VERSION ""

NS_ :

BS_:

BU_: XXX CLOCK HUD H_U DATC CCP KMA_TMU CUBIS TMU IPM RSE_R RRC CGW RSE_L AMP EDT SWRC IBOX CLU FHCU ASD MON AVM KBD IAP ODS _4WD BCM MDPS AAF_Tester AEMC SMK EPB MTS EVP TPMS LPI DI_BOX SPAS EMS LCA TCU FATC AFLS FPCM SCC AHLS ABS SNV OPI PGS SAS AAF Dummy LDWS_LKAS LVR ESC PSB ECS ACU REA

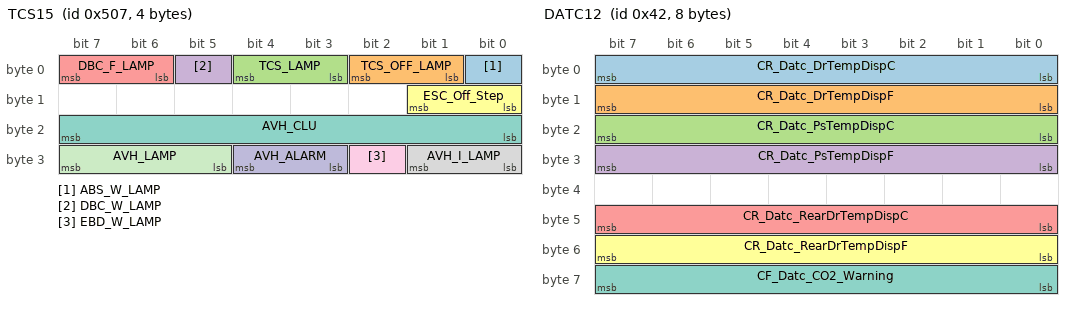
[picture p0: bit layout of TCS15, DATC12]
BO_ 1287 TCS15: 4 ESC
 SG_ ABS_W_LAMP : 0|1@1+ (1.0,0.0) [0.0|1.0] ""  _4WD,CLU,CUBIS,IBOX
 SG_ TCS_OFF_LAMP : 1|2@1+ (1.0,0.0) [0.0|1.0] ""  _4WD,ACU,CLU
 SG_ TCS_LAMP : 3|2@1+ (1.0,0.0) [0.0|3.0] ""  _4WD,ACU,CLU,CUBIS,IBOX,SCC
 SG_ DBC_W_LAMP : 5|1@1+ (1.0,0.0) [0.0|1.0] ""  _4WD,CLU
 SG_ DBC_F_LAMP : 6|2@1+ (1.0,0.0) [0.0|3.0] ""  _4WD,CLU
 SG_ ESC_Off_Step : 8|2@1+ (1.0,0.0) [0.0|3.0] ""  CLU
 SG_ AVH_CLU : 16|8@1+ (1.0,0.0) [0.0|255.0] ""  CLU,EPB
 SG_ AVH_I_LAMP : 24|2@1+ (1.0,0.0) [0.0|3.0] ""  EPB
 SG_ EBD_W_LAMP : 26|1@1+ (1.0,0.0) [0.0|1.0] ""  _4WD,CLU
 SG_ AVH_ALARM : 27|2@1+ (1.0,0.0) [0.0|3.0] ""  CLU
 SG_ AVH_LAMP : 29|3@1+ (1.0,0.0) [0.0|7.0] ""  CLU,EPB,SPAS

BO_ 916 TCS13: 8 ESC
 SG_ aBasis : 0|11@1+ (0.01,-10.23) [-10.23|10.24] "m/s^2"  EMS,SCC
 SG_ BrakeLight : 11|1@1+ (1.0,0.0) [0.0|1.0] ""  CLU,EMS,SCC
 SG_ DCEnable : 12|1@1+ (1.0,0.0) [0.0|1.0] ""  EMS,SCC
 SG_ AliveCounterTCS : 13|3@1+ (1.0,0.0) [0.0|7.0] ""  EMS,SCC
 SG_ Pre_TCS_CTL : 16|1@1+ (1.0,0.0) [0.0|1.0] ""  Vector__XXX
 SG_ EBA_ACK : 17|1@1+ (1.0,0.0) [0.0|1.0] ""  Vector__XXX
 SG_ FCA_ACK : 18|1@1+ (1.0,0.0) [0.0|1.0] ""  Vector__XXX
 SG_ DF_BF_STAT : 19|2@1+ (1.0,0.0) [0.0|3.0] ""  BCW
 SG_ SCCReqLim : 21|2@1+ (1.0,0.0) [0.0|3.0] ""  SCC
 SG_ TQI_SCC : 23|9@1+ (0.390625,0.0) [0.0|199.609375] "%"  Vector__XXX
 SG_ ACCEL_REF_ACC : 32|11@1+ (0.01,-10.23) [-10.23|10.24] "m/s^2"  EMS,SCC
 SG_ ACCEnable : 43|2@1+ (1.0,0.0) [0.0|3.0] ""  EMS,SCC
 SG_ DriverOverride : 45|2@1+ (1.0,0.0) [0.0|3.0] ""  EMS,SCC
 SG_ StandStill : 47|1@1+ (1.0,0.0) [0.0|1.0] ""  EMS,SCC
 SG_ CheckSum_TCS3 : 48|4@1+ (1.0,0.0) [0.0|15.0] ""  EMS,SCC
 SG_ ACC_EQUIP : 52|1@1+ (1.0,0.0) [0.0|1.0] ""  EMS,SCC
 SG_ PBRAKE_ACT : 53|1@1+ (1.0,0.0) [0.0|1.0] ""  EMS,SCC
 SG_ ACC_REQ : 54|1@1+ (1.0,0.0) [0.0|1.0] ""  EMS
 SG_ DriverBraking : 55|1@1+ (1.0,0.0) [0.0|1.0] ""  EMS,SCC
 SG_ CF_VSM_Coded : 56|1@1+ (1.0,0.0) [0.0|1.0] ""  SCC
 SG_ CF_VSM_Avail : 57|2@1+ (1.0,0.0) [0.0|3.0] ""  CLU,SCC
 SG_ CF_VSM_Handshake : 59|1@1+ (1.0,0.0) [0.0|1.0] ""  SCC
 SG_ CF_DriBkeStat : 60|1@1+ (1.0,0.0) [0.0|1.0] ""  SCC
 SG_ CF_VSM_ConfSwi : 61|2@1+ (1.0,0.0) [0.0|3.0] ""  SCC
 SG_ AEB_EQUIP : 63|1@1+ (1.0,0.0) [0.0|1.0] ""  SCC

BO_ 1345 CGW1: 8 BCM
 SG_ CF_Gway_IGNSw : 0|3@1+ (1.0,0.0) [0.0|7.0] ""  AVM,CLU,ECS,EMS,EPB,ESC,IBOX,LVR,MDPS,SAS,SCC,ECS,EMS,EPB,ESC,IBOX,LVR,MDPS,SAS,SCC
 SG_ CF_Gway_RKECmd : 3|3@1+ (1.0,0.0) [0.0|7.0] ""  CLU,ECS,EMS,IBOX,ECS,EMS,IBOX
 SG_ CF_Gway_DrvKeyLockSw : 6|1@1+ (1.0,0.0) [0.0|1.0] ""  ECS,EMS,IBOX,ECS,EMS,IBOX
 SG_ CF_Gway_DrvKeyUnlockSw : 7|1@1+ (1.0,0.0) [0.0|1.0] ""  ECS,EMS,IBOX,ECS,EMS,IBOX
 SG_ CF_Gway_DrvDrSw : 8|2@1+ (1.0,0.0) [0.0|3.0] ""  CLU,ECS,EMS,EPB,ESC,IBOX,SCC,TCU,ECS,EMS,EPB,ESC,IBOX,SCC,TCU
 SG_ CF_Gway_DrvSeatBeltSw : 10|2@1+ (1.0,0.0) [0.0|3.0] ""  EMS,EPB,ESC,IBOX,PSB,TCU,EMS,EPB,ESC,IBOX,PSB,TCU
 SG_ CF_Gway_TrunkTgSw : 12|2@1+ (1.0,0.0) [0.0|3.0] ""  CLU,ECS,EMS,EPB,ESC,IBOX,ECS,EMS,EPB,ESC,IBOX
 SG_ CF_Gway_AstSeatBeltSw : 14|2@1+ (1.0,0.0) [0.0|3.0] ""  IBOX,PSB,IBOX,PSB
 SG_ CF_Gway_SMKOption : 16|1@1+ (1.0,0.0) [0.0|1.0] ""  CLU,EMS,IBOX,EMS,IBOX,SMK
 SG_ CF_Gway_HoodSw : 17|2@1+ (1.0,0.0) [0.0|3.0] ""  CLU,EMS,EPB,ESC,IBOX,EMS,EPB,ESC,IBOX
 SG_ CF_Gway_TurnSigLh : 19|2@1+ (1.0,0.0) [0.0|3.0] ""  CLU,EMS,IBOX,LCA,LDWS_LKAS,SCC,EMS,IBOX,LCA,LDWS_LKAS,SCC
 SG_ CF_Gway_WiperIntT : 21|3@1+ (1.0,0.0) [0.0|7.0] ""  CLU,EMS,IBOX,LDWS_LKAS,EMS,ESC,IBOX,LDWS_LKAS
 SG_ CF_Gway_WiperIntSw : 24|1@1+ (1.0,0.0) [0.0|1.0] ""  CLU,EMS,IBOX,LDWS_LKAS,EMS,ESC,IBOX,LDWS_LKAS
 SG_ CF_Gway_WiperLowSw : 25|1@1+ (1.0,0.0) [0.0|1.0] ""  CLU,EMS,IBOX,LDWS_LKAS,EMS,ESC,IBOX,LDWS_LKAS
 SG_ CF_Gway_WiperHighSw : 26|1@1+ (1.0,0.0) [0.0|1.0] ""  CLU,EMS,IBOX,LDWS_LKAS,EMS,ESC,IBOX,LDWS_LKAS
 SG_ CF_Gway_WiperAutoSw : 27|1@1+ (1.0,0.0) [0.0|1.0] ""  CLU,EMS,IBOX,LDWS_LKAS,EMS,ESC,IBOX,LDWS_LKAS
 SG_ CF_Gway_RainSnsState : 28|3@1+ (1.0,0.0) [0.0|7.0] ""  AFLS,EMS,IBOX,LDWS_LKAS,AFLS,EMS,ESC,IBOX,LDWS_LKAS
 SG_ CF_Gway_HeadLampLow : 31|1@1+ (1.0,0.0) [0.0|1.0] ""  AFLS,CLU,EMS,IBOX,LDWS_LKAS,SNV,AFLS,EMS,IBOX,LDWS_LKAS,SNV
 SG_ CF_Gway_HeadLampHigh : 32|1@1+ (1.0,0.0) [0.0|1.0] ""  AFLS,CLU,EMS,IBOX,LDWS_LKAS,AFLS,EMS,IBOX,LDWS_LKAS
 SG_ CF_Gway_HazardSw : 33|2@1+ (1.0,0.0) [0.0|3.0] ""  ABS,EMS,ESC,IBOX,LCA,LDWS_LKAS,ABS,EMS,ESC,IBOX,LCA,LDWS_LKAS
 SG_ CF_Gway_AstDrSw : 35|1@1+ (1.0,0.0) [0.0|1.0] ""  CLU,IBOX,IBOX
 SG_ CF_Gway_DefoggerRly : 36|1@1+ (1.0,0.0) [0.0|1.0] ""  EMS,IBOX,EMS,IBOX
 SG_ CF_Gway_ALightStat : 37|1@1+ (1.0,0.0) [0.0|1.0] ""  AFLS,IBOX,LDWS_LKAS,AFLS,IBOX,LDWS_LKAS
 SG_ CF_Gway_LightSwState : 38|2@1+ (1.0,0.0) [0.0|3.0] ""  AFLS,IBOX,LDWS_LKAS,AFLS,IBOX,LDWS_LKAS
 SG_ CF_Gway_Frt_Fog_Act : 40|1@1+ (1.0,0.0) [0.0|1.0] ""  AFLS,CLU,IBOX,LDWS_LKAS,AFLS,IBOX,LDWS_LKAS
 SG_ CF_Gway_TSigRHSw : 41|1@1+ (1.0,0.0) [0.0|1.0] ""  IBOX,LDWS_LKAS,IBOX,LDWS_LKAS
 SG_ CF_Gway_TSigLHSw : 42|1@1+ (1.0,0.0) [0.0|1.0] ""  IBOX,LDWS_LKAS,IBOX,LDWS_LKAS
 SG_ CF_Gway_DriveTypeOption : 43|1@1+ (1.0,0.0) [0.0|1.0] ""  CLU,IBOX,LDWS_LKAS,IBOX,LDWS_LKAS
 SG_ CF_Gway_StarterRlyState : 44|1@1+ (1.0,0.0) [0.0|1.0] ""  EMS,IBOX,EMS,IBOX,SMK
 SG_ CF_Gway_PassiveAccessLock : 45|2@1+ (1.0,0.0) [0.0|7.0] ""  CLU,ECS,EMS,IBOX,ECS,EMS,IBOX,SMK
 SG_ CF_Gway_WiperMistSw : 47|1@1+ (1.0,0.0) [0.0|1.0] ""  CLU,EMS,IBOX,LDWS_LKAS
 SG_ CF_Gway_PassiveAccessUnlock : 48|2@1+ (1.0,0.0) [0.0|7.0] ""  CLU,ECS,EMS,IBOX,ECS,EMS,IBOX,SMK
 SG_ CF_Gway_RrSunRoofOpenState : 50|1@1+ (1.0,0.0) [0.0|1.0] ""  CLU,DATC,IBOX
 SG_ CF_Gway_PassingSW : 51|1@1+ (1.0,0.0) [0.0|1.0] ""  AFLS,IBOX,LDWS_LKAS,AFLS,IBOX,LDWS_LKAS
 SG_ CF_Gway_HBAControlMode : 52|1@1+ (1.0,0.0) [0.0|1.0] ""  IBOX,LDWS_LKAS,IBOX,LDWS_LKAS
 SG_ CF_Gway_HLpHighSw : 53|1@1+ (1.0,0.0) [0.0|1.0] ""  IBOX,LDWS_LKAS,IBOX,LDWS_LKAS
 SG_ CF_Gway_InhibitRMT : 54|2@1+ (1.0,0.0) [0.0|3.0] ""  EMS,EPB,ESC,IBOX,LCA,LDWS_LKAS,MDPS,PGS,SCC,SPAS,TPMS,EPB,ESC,IBOX,LCA,LDWS_LKAS,PGS,SCC,SPAS,TPMS
 SG_ CF_Gway_RainSnsOption : 56|1@1+ (1.0,0.0) [0.0|1.0] ""  CLU
 SG_ C_SunRoofOpenState : 57|1@1+ (1.0,0.0) [0.0|1.0] ""  CLU,DATC,IBOX,DATC,IBOX
 SG_ CF_Gway_Ign1 : 58|1@1+ (1.0,0.0) [0.0|1.0] ""  CLU
 SG_ CF_Gway_Ign2 : 59|1@1+ (1.0,0.0) [0.0|1.0] ""  CLU
 SG_ CF_Gway_ParkBrakeSw : 60|2@1+ (1.0,0.0) [0.0|3.0] ""  CLU,ESC,IBOX,SCC,ESC,IBOX,SCC
 SG_ CF_Gway_TurnSigRh : 62|2@1+ (1.0,0.0) [0.0|3.0] ""  CLU,EMS,IBOX,LCA,LDWS_LKAS,SCC,EMS,IBOX,LCA,LDWS_LKAS,SCC

BO_ 1342 LKAS12: 6 LDWS_LKAS
 SG_ CF_Lkas_TsrSlifOpt : 10|2@1+ (1.0,0.0) [0.0|3.0] ""  CLU
 SG_ CF_LkasTsrStatus : 12|2@1+ (1.0,0.0) [0.0|3.0] ""  CLU
 SG_ CF_Lkas_TsrSpeed_Display_Clu : 16|8@1+ (1.0,0.0) [0.0|255.0] ""  CLU
 SG_ CF_LkasTsrSpeed_Display_Navi : 24|8@1+ (1.0,0.0) [0.0|255.0] ""  BCM,CLU
 SG_ CF_Lkas_TsrAddinfo_Display : 32|2@1+ (1.0,0.0) [0.0|3.0] ""  CLU
 SG_ CF_LkasDawStatus : 40|3@1+ (1,0) [0|7] "" CLU
 SG_ CF_Lkas_Daw_USM : 39|3@1+ (1,0) [0|7] "" CLU

BO_ 832 LKAS11: 8 LDWS_LKAS
    SG_ CF_Lkas_LdwsActivemode : 0|2@1+ (1,0) [0|3] "" CLU,IBOX,PSB
    SG_ CF_Lkas_LdwsSysState : 2|4@1+ (1.0,0.0) [0.0|15.0] ""  CLU,IBOX,PSB
    SG_ CF_Lkas_SysWarning : 6|4@1+ (1.0,0.0) [0.0|15.0] ""  BCM,CLU
    SG_ CF_Lkas_LdwsLHWarning : 10|2@1+ (1.0,0.0) [0.0|3.0] ""  BCM,CLU,PSB
    SG_ CF_Lkas_LdwsRHWarning : 12|2@1+ (1.0,0.0) [0.0|3.0] ""  BCM,CLU,PSB
    SG_ CF_Lkas_HbaLamp : 14|1@1+ (1.0,0.0) [0.0|1.0] ""  CLU
    SG_ CF_Lkas_FcwBasReq : 15|1@1+ (1.0,0.0) [0.0|1.0] ""  ABS,ESC
    SG_ CR_Lkas_StrToqReq : 16|11@1+ (1.0,-1024.0) [-1024.0|1024.0] ""  MDPS
    SG_ CF_Lkas_ActToi : 27|1@1+ (1.0,0.0) [0.0|1.0] ""  MDPS
    SG_ CF_Lkas_ToiFlt : 28|1@1+ (1.0,0.0) [0.0|1.0] ""  MDPS
    SG_ CF_Lkas_HbaSysState : 29|3@1+ (1.0,0.0) [0.0|7.0] ""  BCM,CLU
    SG_ CF_Lkas_FcwOpt : 32|2@1+ (1.0,0.0) [0.0|3.0] ""  CLU
    SG_ CF_Lkas_HbaOpt : 34|2@1+ (1.0,0.0) [0.0|1.0] ""  BCM,CGW
    SG_ CF_Lkas_MsgCount : 36|4@1+ (1.0,0.0) [0.0|15.0] ""  CLU,MDPS
    SG_ CF_Lkas_FcwSysState : 40|3@1+ (1.0,0.0) [0.0|7.0] ""  CLU
    SG_ CF_Lkas_FcwCollisionWarning : 43|2@1+ (1.0,0.0) [0.0|3.0] ""  CLU
    SG_ CF_Lkas_FusionState : 45|2@1+ (1.0,0.0) [0.0|3.0] ""  SCC
    SG_ CF_Lkas_Unknown1 : 47|1@1+ (1.0,0.0) [0.0|1.0] "" XXX
    SG_ CF_Lkas_Chksum : 48|8@1+ (1.0,0.0) [0.0|255.0] ""  MDPS
    SG_ CF_Lkas_FcwOpt_USM : 56|3@1+ (1.0,0.0) [0.0|7.0] ""  CLU
    SG_ CF_Lkas_LdwsOpt_USM : 59|3@1+ (1.0,0.0) [0.0|7.0] ""  CLU,MDPS
    SG_ CF_Lkas_Unknown2 : 62|2@1+ (1.0,0.0) [0.0|1.0] "" XXX

BO_ 52 HU_DATC_E_02: 8 H_U
    SG_ HU_DATC_DrTempUpDn : 1|2@0+ (1,0) [0|0] ""  CGW,CLU,DATC,IPM
    SG_ HU_DATC_PsTempUpDn : 3|2@0+ (1,0) [0|0] ""  CGW,CLU,DATC,IPM
    SG_ HU_DATC_RlTempUpDn : 5|2@0+ (1,0) [0|0] ""  CGW,CLU,DATC,IPM
    SG_ HU_DATC_RrTempUpDn : 7|2@0+ (1,0) [0|0] ""  CGW,CLU,DATC,IPM
    SG_ HU_DATC_MainBlower : 11|4@0+ (1,0) [0|0] ""  CGW,CLU,DATC,IPM
    SG_ HU_DATC_SubBlower : 15|4@0+ (1,0) [0|0] ""  CGW,CLU,DATC,IPM
    SG_ HU_DATC_RearBlower : 19|4@0+ (1,0) [0|0] ""  CGW,CLU,DATC,IPM
    SG_ HU_DATCRearPsModeSet : 23|4@0+ (1,0) [0|0] ""  CGW,CLU
    SG_ HU_DATC_FrontModeSet : 27|4@0+ (1,0) [0|0] ""  CGW,CLU,DATC,IPM
    SG_ HU_DATC_RearModeSet : 31|4@0+ (1,0) [0|0] ""  CGW,CLU,DATC,IPM
    SG_ HU_DATC_AutoSet : 33|2@0+ (1,0) [0|0] ""  CGW,CLU,DATC,IPM
    SG_ HU_DATC_OffReq : 35|2@0+ (1,0) [0|0] ""  CGW,CLU,DATC,IPM
    SG_ HU_DATC_IntakeSet : 37|2@0+ (1,0) [0|0] ""  CGW,CLU,DATC,IPM
    SG_ HU_DATC_RearOnOffSet : 39|2@0+ (1,0) [0|0] ""  CGW,CLU,DATC,IPM
    SG_ HU_DATC_AcSet : 41|2@0+ (1,0) [0|0] ""  CGW,CLU,DATC,IPM
    SG_ HU_DATC_AqsSet : 43|2@0+ (1,0) [0|0] ""  CGW,CLU,DATC,IPM
    SG_ HU_DATC_FrontDefog : 45|2@0+ (1,0) [0|0] ""  CGW,CLU,DATC,IPM
    SG_ HU_DATC_RearDefog : 47|2@0+ (1,0) [0|0] ""  CGW,CLU,DATC,IPM
    SG_ HU_DATC_ZoneControl : 49|2@0+ (1,0) [0|0] ""  CGW,CLU,DATC,IPM
    SG_ HU_DATC_CO2Set : 51|2@0+ (1,0) [0|0] ""  CGW,CLU,DATC,IPM
    SG_ DATC_SmartVentOnOffSet : 53|2@0+ (1,0) [0|0] ""  CGW,CLU,DATC,IPM
    SG_ DATC_ADSOnOffSet : 55|2@0+ (1,0) [0|0] ""  CGW,CLU
    SG_ HU_DATC_RearAutoDisp : 57|2@0+ (1,0) [0|0] ""  CGW,CLU
    SG_ HU_DATC_RearOffDisp : 59|2@0+ (1,0) [0|0] ""  CGW,CLU

BO_ 66 DATC12: 8 DATC
    SG_ CR_Datc_DrTempDispC : 0|8@1+ (0.5,14.0) [15.0|32.0] "deg"  CLU,IBOX
    SG_ CR_Datc_DrTempDispF : 8|8@1+ (1.0,56.0) [58.0|90.0] "deg"  CLU,IBOX
    SG_ CR_Datc_PsTempDispC : 16|8@1+ (0.5,14.0) [15.0|32.0] "deg"  CLU,IBOX
    SG_ CR_Datc_PsTempDispF : 24|8@1+ (1.0,56.0) [58.0|90.0] "deg"  CLU,IBOX
    SG_ CR_Datc_RearDrTempDispC : 40|8@1+ (0.5,14.0) [15.0|32.0] "deg"  CLU
    SG_ CR_Datc_RearDrTempDispF : 48|8@1+ (1.0,58.0) [58.0|90.0] "deg"  CLU
    SG_ CF_Datc_CO2_Warning : 56|8@1+ (1.0,0.0) [0.0|3.0] ""  CLU

BO_ 67 DATC13: 8 DATC
    SG_ CF_Datc_TempDispUnit : 0|2@1+ (1.0,0.0) [0.0|3.0] ""  CLU,IBOX
    SG_ CF_Datc_ModDisp : 2|4@1+ (1.0,0.0) [0.0|15.0] ""  CLU
    SG_ CF_Datc_IonClean : 6|2@1+ (1.0,0.0) [0.0|3.0] ""  CLU
    SG_ CF_Datc_ChgReqDisp : 8|2@1+ (1.0,0.0) [0.0|3.0] ""  CLU
    SG_ CF_Datc_IntakeDisp : 10|2@1+ (1.0,0.0) [0.0|3.0] ""  CLU
    SG_ CF_Datc_AutoDisp : 12|2@1+ (1.0,0.0) [0.0|3.0] ""  CLU
    SG_ CF_Datc_FrDefLed : 14|2@1+ (1.0,0.0) [0.0|3.0] ""  CLU,IBOX
    SG_ CF_Datc_AutoDefogBlink : 16|2@1+ (1.0,0.0) [0.0|3.0] ""  CLU
    SG_ CF_Datc_ClmScanDisp : 18|2@1+ (1.0,0.0) [0.0|3.0] ""  CLU
    SG_ CF_Datc_AqsDisp : 20|2@1+ (1.0,0.0) [0.0|3.0] ""  CLU
    SG_ CF_Datc_AcDisp : 22|2@1+ (1.0,0.0) [0.0|3.0] ""  CLU
    SG_ CF_Datc_OpSts : 25|3@1+ (1.0,0.0) [0.0|7.0] ""  CLU
    SG_ CF_Mtc_MaxAcDisp : 28|2@1+ (1.0,0.0) [0.0|3.0] ""  CLU
    SG_ CF_Datc_DualDisp : 30|2@1+ (1.0,0.0) [0.0|3.0] ""  CLU
    SG_ CF_Datc_PwrInf : 32|4@1+ (1.0,0.0) [0.0|15.0] ""  CLU
    SG_ CF_Datc_RearManual : 38|2@1+ (1.0,0.0) [0.0|3.0] ""  CLU
    SG_ CF_Datc_RearAutoDisp : 40|2@1+ (1.0,0.0) [0.0|1.0] ""  CLU
    SG_ CF_Datc_RearOffDisp : 42|2@1+ (1.0,0.0) [0.0|3.0] ""  CLU
    SG_ CF_Datc_RearClimateScnDisp : 44|2@1+ (1.0,0.0) [0.0|3.0] ""  CLU
    SG_ CF_Datc_RearChgReqDisp : 46|2@1+ (1.0,0.0) [0.0|3.0] ""  CLU
    SG_ CF_Datc_RearModDisp : 48|4@1+ (1.0,0.0) [0.0|15.0] ""  CLU
    SG_ CF_Datc_RearBlwDisp : 52|4@1+ (1.0,0.0) [0.0|15.0] ""  CLU
    SG_ CF_Datc_PSModDisp : 56|4@1+ (1.0,0.0) [0.0|15.0] ""  CLU
    SG_ CF_Datc_FrontBlwDisp : 60|4@1+ (1.0,0.0) [0.0|15.0] ""  CLU,IBOX

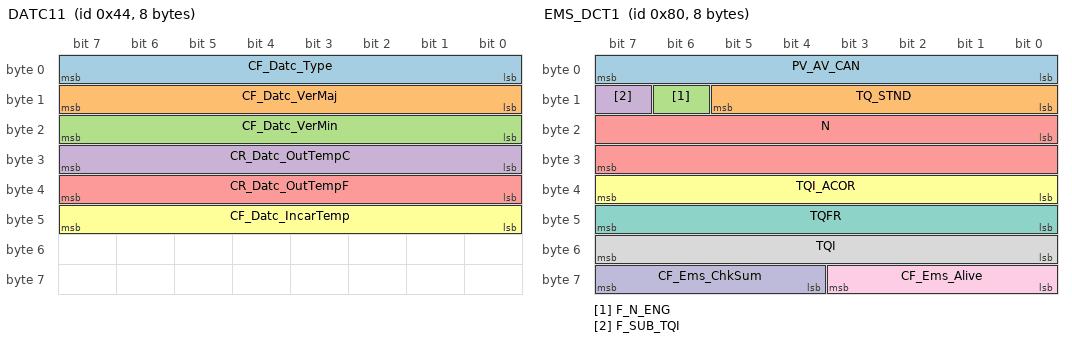
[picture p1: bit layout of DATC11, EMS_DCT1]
BO_ 68 DATC11: 8 DATC
    SG_ CF_Datc_Type : 0|8@1+ (1.0,0.0) [0.0|255.0] ""  CLU
    SG_ CF_Datc_VerMaj : 8|8@1+ (1.0,0.0) [0.0|255.0] ""  CLU
    SG_ CF_Datc_VerMin : 16|8@1+ (1.0,0.0) [0.0|255.0] ""  CLU
    SG_ CR_Datc_OutTempC : 24|8@1+ (0.5,-41.0) [-41.0|86.5] "deg"  CLU,FPCM
    SG_ CR_Datc_OutTempF : 32|8@1+ (1.0,-42.0) [-42.0|213.0] "deg"  CLU
    SG_ CF_Datc_IncarTemp : 40|8@1+ (0.5,-40.0) [-40.0|60.0] "deg"  BCM,CLU

BO_ 128 EMS_DCT1: 8 XXX
    SG_ PV_AV_CAN : 0|8@1+ (0.3906,0) [0|99.603] "%" XXX
    SG_ TQ_STND : 8|6@1+ (10,0) [0|630] "Nm" XXX
    SG_ F_N_ENG : 14|1@1+ (1,0) [0|1] "" XXX
    SG_ F_SUB_TQI : 15|1@1+ (1,0) [0|1] "" XXX
    SG_ N : 16|16@1+ (0.25,0) [0|16383.8] "rpm" XXX
    SG_ TQI_ACOR : 32|8@1+ (0.390625,0) [0|99.6094] "%" XXX
    SG_ TQFR : 40|8@1+ (0.390625,0) [0|99.6094] "%" XXX
    SG_ TQI : 48|8@1+ (0.390625,0) [0|99.6094] "%" XXX
    SG_ CF_Ems_Alive : 56|4@1+ (1,0) [0|15] "" XXX
    SG_ CF_Ems_ChkSum : 60|4@1+ (1,0) [0|15] "" XXX

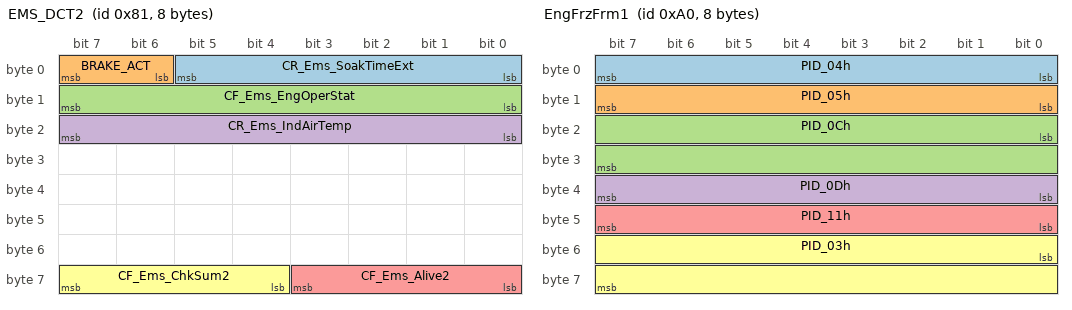
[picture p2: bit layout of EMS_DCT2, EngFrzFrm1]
BO_ 129 EMS_DCT2: 8 XXX
    SG_ CR_Ems_SoakTimeExt : 0|6@1+ (5,0) [0|315] "Min" XXX
    SG_ BRAKE_ACT : 6|2@1+ (1,0) [0|3] "" XXX
    SG_ CF_Ems_EngOperStat : 8|8@1+ (1,0) [0|255] "" XXX
    SG_ CR_Ems_IndAirTemp : 16|8@1+ (0.75,-48) [-48|143.25] "" XXX
    SG_ CF_Ems_Alive2 : 56|4@1+ (1,0) [0|15] "" XXX
    SG_ CF_Ems_ChkSum2 : 60|4@1+ (1,0) [0|15] "" XXX

BO_ 160 EngFrzFrm1: 8 XXX
    SG_ PID_04h : 0|8@1+ (0.392157,0) [0|100] "%" XXX
    SG_ PID_05h : 8|8@1+ (1,-40) [-40|215] "" XXX
    SG_ PID_0Ch : 16|16@1+ (0.25,0) [0|16383.8] "rpm" XXX
    SG_ PID_0Dh : 32|8@1+ (1,0) [0|255] "km/h" XXX
    SG_ PID_11h : 40|8@1+ (0.392157,0) [0|100] "%" XXX
    SG_ PID_03h : 48|16@1+ (1,0) [0|65535] "" XXX

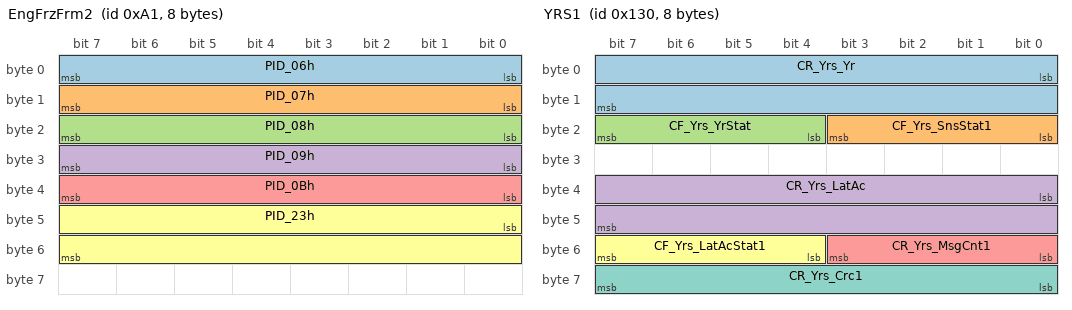
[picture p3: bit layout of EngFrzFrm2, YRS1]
BO_ 161 EngFrzFrm2: 8 XXX
    SG_ PID_06h : 0|8@1+ (0.78125,-100) [-100|99.22] "%" XXX
    SG_ PID_07h : 8|8@1+ (0.78125,-100) [-100|99.22] "%" XXX
    SG_ PID_08h : 16|8@1+ (0.78125,-100) [-100|99.22] "%" XXX
    SG_ PID_09h : 24|8@1+ (0.78125,-100) [-100|99.22] "%" XXX
    SG_ PID_0Bh : 32|8@1+ (1,0) [0|255] "kPa" XXX
    SG_ PID_23h : 40|16@1+ (10,0) [0|655350] "kPa" XXX

BO_ 304 YRS1: 8 XXX
    SG_ CR_Yrs_Yr : 0|16@1+ (0.005,-163.84) [-163.84|163.83] "" XXX
    SG_ CF_Yrs_SnsStat1 : 16|4@1+ (1,0) [0|15] "" XXX
    SG_ CF_Yrs_YrStat : 20|4@1+ (1,0) [0|15] "" XXX
    SG_ CR_Yrs_LatAc : 32|16@1+ (0.000127465,-4.17677) [-4.17677|4.17652] "g" XXX
    SG_ CR_Yrs_MsgCnt1 : 48|4@1+ (1,0) [0|15] "" XXX
    SG_ CF_Yrs_LatAcStat1 : 52|4@1+ (1,0) [0|15] "" XXX
    SG_ CR_Yrs_Crc1 : 56|8@1+ (1,0) [0|255] "" XXX

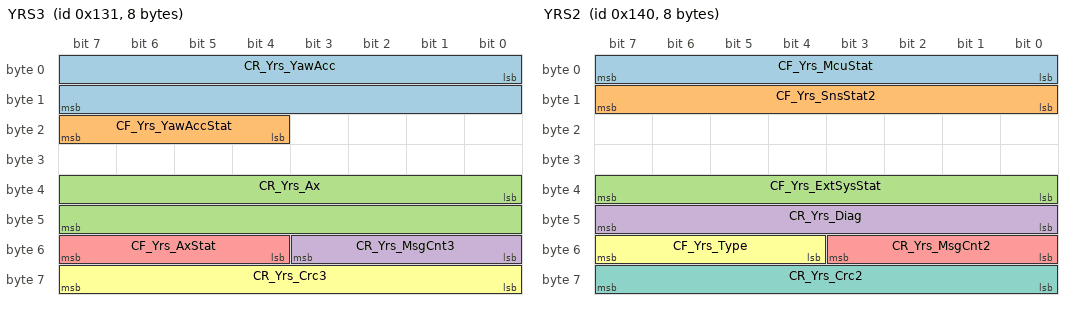
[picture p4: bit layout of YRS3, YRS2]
BO_ 305 YRS3: 8 XXX
    SG_ CR_Yrs_YawAcc : 0|16@1+ (0.125,-4096) [-4096|4095.75] "" XXX
    SG_ CF_Yrs_YawAccStat : 20|4@1+ (1,0) [0|15] "" XXX
    SG_ CR_Yrs_Ax : 32|16@1+ (0.000127465,-4.17677) [-4.17677|4.17652] "g" XXX
    SG_ CR_Yrs_MsgCnt3 : 48|4@1+ (1,0) [0|15] "" XXX
    SG_ CF_Yrs_AxStat : 52|4@1+ (1,0) [0|15] "" XXX
    SG_ CR_Yrs_Crc3 : 56|8@1+ (1,0) [0|255] "" XXX

BO_ 320 YRS2: 8 XXX
    SG_ CF_Yrs_McuStat : 0|8@1+ (1,0) [0|255] "" XXX
    SG_ CF_Yrs_SnsStat2 : 8|8@1+ (1,0) [0|255] "" XXX
    SG_ CF_Yrs_ExtSysStat : 32|8@1+ (1,0) [0|255] "" XXX
    SG_ CR_Yrs_Diag : 40|8@1+ (1,0) [0|255] "" XXX
    SG_ CR_Yrs_MsgCnt2 : 48|4@1+ (1,0) [0|15] "" XXX
    SG_ CF_Yrs_Type : 52|4@1+ (1,0) [0|15] "" XXX
    SG_ CR_Yrs_Crc2 : 56|8@1+ (1,0) [0|255] "" XXX

BO_ 339 TCS11: 8 ESC
    SG_ TCS_REQ : 0|1@1+ (1.0,0.0) [0.0|1.0] ""  _4WD,EMS,EPB,TCU
    SG_ MSR_C_REQ : 1|1@1+ (1.0,0.0) [0.0|1.0] ""  EMS,EPB,SCC,TCU
    SG_ TCS_PAS : 2|1@1+ (1.0,0.0) [0.0|1.0] ""  _4WD,CLU,EMS,SCC,SPAS,TCU
    SG_ TCS_GSC : 3|1@1+ (1.0,0.0) [0.0|1.0] ""  _4WD,EMS,TCU
    SG_ CF_Esc_LimoInfo : 4|2@1+ (1.0,0.0) [0.0|3.0] ""  _4WD,SCC
    SG_ ABS_DIAG : 6|1@1+ (1.0,0.0) [0.0|1.0] ""  _4WD,CLU,EMS,EPB
    SG_ ABS_DEF : 7|1@1+ (1.0,0.0) [0.0|1.0] ""  _4WD,ACU,ECS,EMS,EPB,SCC,SPAS,TCU
    SG_ TCS_DEF : 8|1@1+ (1.0,0.0) [0.0|1.0] ""  _4WD,EMS,EPB,SCC,SPAS,TCU
    SG_ TCS_CTL : 9|1@1+ (1.0,0.0) [0.0|1.0] ""  _4WD,EMS,EPB,SCC,SPAS,TCU
    SG_ ABS_ACT : 10|1@1+ (1.0,0.0) [0.0|1.0] ""  _4WD,ACU,ECS,EMS,EPB,LDWS_LKAS,SCC,SPAS,TCU
    SG_ EBD_DEF : 11|1@1+ (1.0,0.0) [0.0|1.0] ""  _4WD,EMS,EPB,SPAS,TCU
    SG_ ESP_PAS : 12|1@1+ (1.0,0.0) [0.0|1.0] ""  _4WD,ACU,CLU,EMS,EPB,LDWS_LKAS,SCC,TCU
    SG_ ESP_DEF : 13|1@1+ (1.0,0.0) [0.0|1.0] ""  _4WD,ACU,ECS,EMS,EPB,LDWS_LKAS,SCC,TCU
    SG_ ESP_CTL : 14|1@1+ (1.0,0.0) [0.0|1.0] ""  _4WD,ACU,ECS,EMS,EPB,LDWS_LKAS,SCC,SPAS,TCU
    SG_ TCS_MFRN : 15|1@1+ (1.0,0.0) [0.0|1.0] ""  EMS,EPB,TCU
    SG_ DBC_CTL : 16|1@1+ (1.0,0.0) [0.0|1.0] ""  _4WD,EMS,EPB
    SG_ DBC_PAS : 17|1@1+ (1.0,0.0) [0.0|1.0] ""  _4WD,EMS,EPB
	SG_ DBC_DEF : 18|1@1+ (1.0,0.0) [0.0|1.0] ""  _4WD,EMS,EPB
    SG_ HAC_CTL : 19|1@1+ (1.0,0.0) [0.0|1.0] ""  _4WD,CLU,EMS,EPB,TCU
    SG_ HAC_PAS : 20|1@1+ (1.0,0.0) [0.0|1.0] ""  _4WD,CLU,EMS,EPB,TCU
    SG_ HAC_DEF : 21|1@1+ (1.0,0.0) [0.0|1.0] ""  _4WD,CLU,EMS,EPB,TCU
    SG_ ESS_STAT : 22|2@1+ (1.0,0.0) [0.0|3.0] ""  _4WD,BCM,CLU,EMS,EPB
    SG_ TQI_TCS : 24|8@1+ (0.390625,0.0) [0.0|99.609375] "%"  EMS,EPB,TCU
    SG_ TQI_MSR : 32|8@1+ (0.390625,0.0) [0.0|99.609375] "%"  EMS,EPB,TCU
    SG_ TQI_SLW_TCS : 40|8@1+ (0.390625,0.0) [0.0|99.609375] "%"  EMS,EPB,TCU
    SG_ CF_Esc_BrkCtl : 48|1@1+ (1.0,0.0) [0.0|1.0] ""  EMS
    SG_ BLA_CTL : 49|2@1+ (1.0,0.0) [0.0|3.0] ""  BCM,CGW,CLU
    SG_ AliveCounter_TCS1 : 52|4@1+ (1.0,0.0) [0.0|14.0] ""  EMS,EPB,LDWS_LKAS
    SG_ CheckSum_TCS1 : 56|8@1+ (1.0,0.0) [0.0|255.0] ""  EMS,EPB,LDWS_LKAS

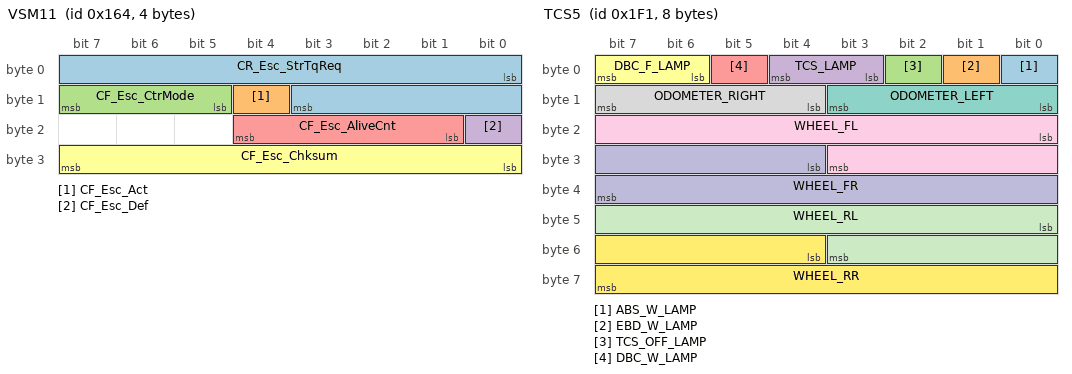
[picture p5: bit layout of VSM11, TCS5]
BO_ 356 VSM11: 4 ESC
    SG_ CR_Esc_StrTqReq : 0|12@1+ (0.01,-20.48) [-20.48|20.47] "Nm"  MDPS
    SG_ CF_Esc_Act : 12|1@1+ (1.0,0.0) [0.0|1.0] ""  LDWS_LKAS,MDPS
    SG_ CF_Esc_CtrMode : 13|3@1+ (1.0,0.0) [0.0|7.0] ""  MDPS
    SG_ CF_Esc_Def : 16|1@1+ (1.0,0.0) [0.0|1.0] ""  MDPS
    SG_ CF_Esc_AliveCnt : 17|4@1+ (1.0,0.0) [0.0|15.0] ""  LDWS_LKAS,MDPS
    SG_ CF_Esc_Chksum : 24|8@1+ (1.0,0.0) [0.0|255.0] ""  LDWS_LKAS,MDPS

BO_ 357 S_MDPS12: 8 XXX
    SG_ NEW_SIGNAL_1 : 0|12@1+ (1,0) [0|4095] "" XXX
    SG_ NEW_SIGNAL_2 : 12|12@1+ (1,0) [0|4095] "" XXX
    SG_ Counter : 48|4@1+ (1,0) [0|15] "" XXX
    SG_ Checksum : 63|8@0+ (1,0) [0|255] "" XXX

BO_ 399 EMS_H12: 8 EMS
    SG_ R_TqAcnApvC : 0|8@1+ (0.2,0.0) [0.0|51.0] "Nm"  DATC,IBOX
    SG_ R_PAcnC : 8|8@1+ (125.0,0.0) [0.0|31875.0] "hPa"  DATC,IBOX
    SG_ TQI_B : 16|8@1+ (0.390625,0.0) [0.0|99.609375] "%"  ABS,ESC,IBOX
    SG_ SLD_VS : 24|8@1+ (1.0,0.0) [0.0|255.0] "km/h"  CLU,IBOX
    SG_ CF_CdaStat : 32|3@1+ (1.0,0.0) [0.0|7.0] ""  AEMC,IBOX,TCU
    SG_ CF_Ems_IsgStat : 35|3@1+ (1.0,0.0) [0.0|7.0] ""  ABS,BCM,CLU,DATC,EPB,ESC,IBOX,LDWS_LKAS,MDPS,SMK,TCU
    SG_ CF_Ems_OilChg : 38|1@1+ (1.0,0.0) [0.0|1.0] ""  CLU,IBOX
    SG_ CF_Ems_EtcLimpMod : 39|1@1+ (1.0,0.0) [0.0|1.0] ""  CLU,IBOX
    SG_ R_NEngIdlTgC : 40|8@1+ (10.0,0.0) [0.0|2550.0] "rpm"  DATC,IBOX,TCU
    SG_ CF_Ems_UpTarGr : 48|1@1+ (1.0,0.0) [0.0|1.0] ""  CLU,IBOX
    SG_ CF_Ems_DownTarGr : 49|1@1+ (1.0,0.0) [0.0|1.0] ""  CLU,IBOX
    SG_ CF_Ems_DesCurGr : 50|4@1+ (1.0,0.0) [0.0|15.0] ""  CLU,IBOX
    SG_ CF_Ems_SldAct : 54|1@1+ (1.0,0.0) [0.0|1.0] ""  CLU,IBOX
    SG_ CF_Ems_SldPosAct : 55|1@1+ (1.0,0.0) [0.0|1.0] ""  CLU,IBOX
    SG_ CF_Ems_HPresStat : 56|1@1+ (1.0,0.0) [0.0|1.0] ""  IBOX,TCU
    SG_ CF_Ems_IsgBuz : 57|1@1+ (1.0,0.0) [0.0|1.0] ""  CLU,IBOX
    SG_ CF_Ems_IdlStpFCO : 58|1@1+ (1.0,0.0) [0.0|1.0] ""  CLU,IBOX
    SG_ CF_Ems_FCopen : 59|1@1+ (1.0,0.0) [0.0|1.0] ""  CLU,IBOX
    SG_ CF_Ems_ActEcoAct : 60|1@1+ (1.0,0.0) [0.0|1.0] ""  CLU,IBOX,TCU
    SG_ CF_Ems_EngRunNorm : 61|1@1+ (1.0,0.0) [0.0|1.0] ""  ABS,ESC,IBOX,TCU
    SG_ CF_Ems_IsgStat2 : 62|2@1+ (2.0,0.0) [0.0|3.0] ""  CLU,IBOX,TCU

BO_ 497 TCS5: 8 XXX
    SG_ ABS_W_LAMP : 0|1@1+ (1,0) [0|1] "" XXX
    SG_ EBD_W_LAMP : 1|1@1+ (1,0) [0|1] "" XXX
    SG_ TCS_OFF_LAMP : 2|1@1+ (1,0) [0|1] "" XXX
    SG_ TCS_LAMP : 3|2@1+ (1,0) [0|3] "" XXX
    SG_ DBC_W_LAMP : 5|1@1+ (1,0) [0|1] "" XXX
    SG_ DBC_F_LAMP : 6|2@1+ (1,0) [0|3] "" XXX
    SG_ ODOMETER_LEFT : 8|4@1+ (1,0) [0|15] "m" XXX
    SG_ ODOMETER_RIGHT : 12|4@1+ (1,0) [0|15] "m" XXX
    SG_ WHEEL_FL : 16|12@1+ (0.125,0) [0|511.875] "km/h" XXX
    SG_ WHEEL_FR : 28|12@1+ (0.125,0) [0|511.875] "km/h" XXX
    SG_ WHEEL_RL : 40|12@1+ (0.125,0) [0|511.875] "km/h" XXX
    SG_ WHEEL_RR : 52|12@1+ (0.125,0) [0|511.875] "km/h" XXX

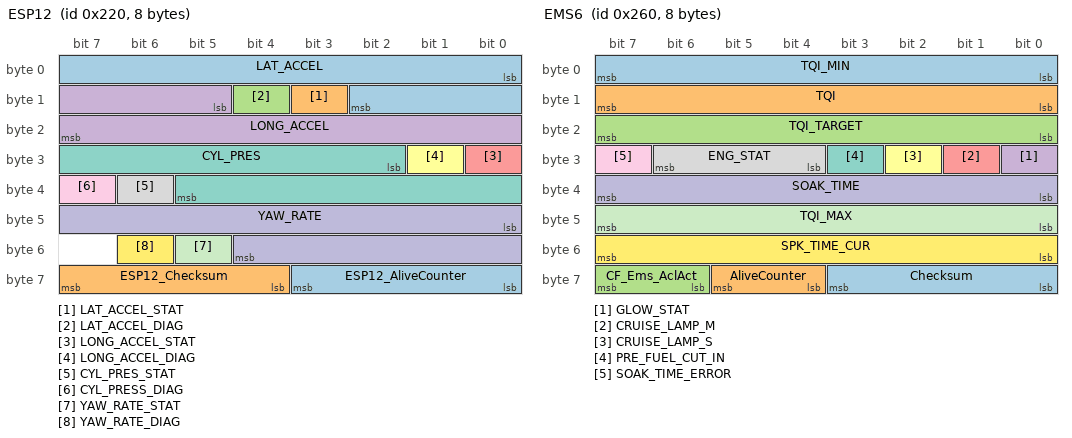
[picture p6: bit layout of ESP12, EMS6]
BO_ 544 ESP12: 8 ESC
    SG_ LAT_ACCEL : 0|11@1+ (0.01,-10.23) [-10.23|10.24] "m/s^2"  _4WD,ECS,IBOX,LCA,LDWS_LKAS,MDPS,PSB,SCC,TCU
    SG_ LAT_ACCEL_STAT : 11|1@1+ (1.0,0.0) [0.0|1.0] ""  _4WD,IBOX,LDWS_LKAS,MDPS,PSB,SCC,TCU
    SG_ LAT_ACCEL_DIAG : 12|1@1+ (1.0,0.0) [0.0|1.0] ""  _4WD,IBOX,LDWS_LKAS,MDPS,PSB,SCC,TCU
    SG_ LONG_ACCEL : 13|11@1+ (0.01,-10.23) [-10.23|10.24] "m/s^2"  _4WD,ECS,EMS,EPB,IBOX,LCA,LDWS_LKAS,PSB,SCC,SPAS,TCU
    SG_ LONG_ACCEL_STAT : 24|1@1+ (1.0,0.0) [0.0|1.0] ""  _4WD,EMS,EPB,IBOX,LDWS_LKAS,PSB,SCC,SPAS,TCU
    SG_ LONG_ACCEL_DIAG : 25|1@1+ (1.0,0.0) [0.0|1.0] ""  _4WD,EMS,EPB,IBOX,LDWS_LKAS,PSB,SCC,SPAS,TCU
    SG_ CYL_PRES : 26|12@1+ (0.1,0.0) [0.0|409.5] "Bar"  _4WD,ECS,EMS,EPB,IBOX,LDWS_LKAS,PSB,SCC,TCU
    SG_ CYL_PRES_STAT : 38|1@1+ (1.0,0.0) [0.0|1.0] ""  _4WD,ECS,EMS,EPB,IBOX,LDWS_LKAS,PSB,SCC,TCU
    SG_ CYL_PRESS_DIAG : 39|1@1+ (1.0,0.0) [0.0|1.0] ""  _4WD,ECS,EMS,EPB,IBOX,PSB,SCC,TCU
    SG_ YAW_RATE : 40|13@1+ (0.01,-40.95) [-40.95|40.96] ""  _4WD,AFLS,IBOX,LCA,LDWS_LKAS,MDPS,PSB,SCC,SPAS,TCU
    SG_ YAW_RATE_STAT : 53|1@1+ (1.0,0.0) [0.0|1.0] ""  _4WD,AFLS,IBOX,LCA,LDWS_LKAS,MDPS,PSB,SCC,SPAS,TCU
    SG_ YAW_RATE_DIAG : 54|1@1+ (1.0,0.0) [0.0|1.0] ""  _4WD,AFLS,IBOX,LCA,LDWS_LKAS,MDPS,PSB,SCC,SPAS,TCU
    SG_ ESP12_AliveCounter : 56|4@1+ (1.0,0.0) [0.0|15.0] ""  _4WD,EMS,LPI,TCU,TMU
    SG_ ESP12_Checksum : 60|4@1+ (1.0,0.0) [0.0|15.0] ""  _4WD,EMS,LPI,TCU,TMU

BO_ 608 EMS6: 8 XXX
    SG_ TQI_MIN : 0|8@1+ (0.390625,0) [0|99.6094] "%" XXX
    SG_ TQI : 8|8@1+ (0.390625,0) [0|99.6094] "%" XXX
    SG_ TQI_TARGET : 16|8@1+ (0.390625,0) [0|99.6094] "%" XXX
    SG_ GLOW_STAT : 24|1@1+ (1,0) [0|1] "" XXX
    SG_ CRUISE_LAMP_M : 25|1@1+ (1,0) [0|1] "" XXX
    SG_ CRUISE_LAMP_S : 26|1@1+ (1,0) [0|1] "" XXX
    SG_ PRE_FUEL_CUT_IN : 27|1@1+ (1,0) [0|1] "" XXX
    SG_ ENG_STAT : 28|3@1+ (1,0) [0|7] "" XXX
    SG_ SOAK_TIME_ERROR : 31|1@1+ (1,0) [0|1] "" XXX
    SG_ SOAK_TIME : 32|8@1+ (1,0) [0|255] "Min" XXX
    SG_ TQI_MAX : 40|8@1+ (0.390625,0) [0|99.6094] "%" XXX
    SG_ SPK_TIME_CUR : 48|8@1+ (0.375,-35.625) [-35.625|60] "" XXX
    SG_ Checksum : 56|4@1+ (1,0) [0|15] "" XXX
    SG_ AliveCounter : 60|2@1+ (1,0) [0|3] "" XXX
    SG_ CF_Ems_AclAct : 62|2@1+ (1,0) [0|3] "" XXX

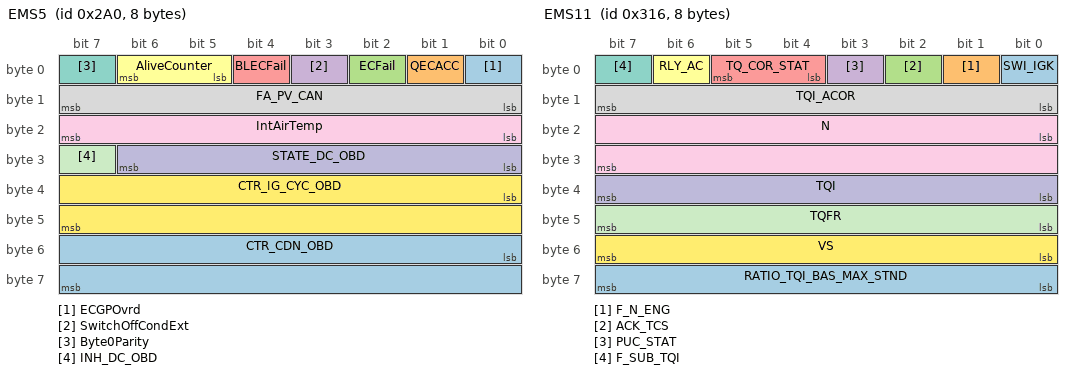
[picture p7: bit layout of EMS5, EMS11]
BO_ 672 EMS5: 8 XXX
    SG_ ECGPOvrd : 0|1@1+ (1,0) [0|1] "" XXX
    SG_ QECACC : 1|1@1+ (1,0) [0|1] "" XXX
    SG_ ECFail : 2|1@1+ (1,0) [0|1] "" XXX
    SG_ SwitchOffCondExt : 3|1@1+ (1,0) [0|1] "" XXX
    SG_ BLECFail : 4|1@1+ (1,0) [0|1] "" XXX
    SG_ AliveCounter : 5|2@1+ (1,0) [0|3] "" XXX
    SG_ Byte0Parity : 7|1@1+ (1,0) [0|1] "" XXX
    SG_ FA_PV_CAN : 8|8@1+ (0.3906,0) [0|99.2] "%" XXX
    SG_ IntAirTemp : 16|8@1+ (0.75,-48) [-48|143.25] "" XXX
    SG_ STATE_DC_OBD : 24|7@1+ (1,0) [0|127] "" XXX
    SG_ INH_DC_OBD : 31|1@1+ (1,0) [0|1] "" XXX
    SG_ CTR_IG_CYC_OBD : 32|16@1+ (1,0) [0|65535] "" XXX
    SG_ CTR_CDN_OBD : 48|16@1+ (1,0) [0|65535] "" XXX

BO_ 688 SAS11: 5 MDPS
    SG_ SAS_Angle : 0|16@1- (0.1,0.0) [-3276.8|3276.7] "Deg"  _4WD,ACU,AFLS,AVM,CLU,ECS,EMS,ESC,IBOX,LCA,LDWS_LKAS,PGS,PSB,SCC,SPAS,TCU,_4WD,ACU,AFLS,AVM,BCM,CLU,ECS,EMS,ESC,IBOX,LCA,LDWS_LKAS,PGS,PSB,SCC,SPAS,TCU
    SG_ SAS_Speed : 16|8@1+ (4.0,0.0) [0.0|1016.0] ""  AFLS,ECS,ESC,IBOX,LDWS_LKAS,SCC,SPAS,TCU,AFLS,ECS,ESC,IBOX,LDWS_LKAS,SCC,SPAS,TCU
    SG_ SAS_Stat : 24|8@1+ (1.0,0.0) [0.0|255.0] ""  ECS,ESC,IBOX,LDWS_LKAS,PSB,SCC,SPAS,TCU,ECS,ESC,IBOX,LDWS_LKAS,PSB,SCC,SPAS,TCU
    SG_ MsgCount : 32|4@1+ (1.0,0.0) [0.0|15.0] ""  ECS,ESC,IBOX,LDWS_LKAS,PSB,SCC,SPAS,ECS,ESC,IBOX,LDWS_LKAS,PSB,SCC,SPAS
    SG_ CheckSum : 36|4@1+ (1.0,0.0) [0.0|15.0] ""  ECS,EMS,ESC,IBOX,LDWS_LKAS,PSB,SCC,SPAS,ECS,EMS,ESC,IBOX,LDWS_LKAS,PSB,SCC,SPAS

BO_ 790 EMS11: 8 EMS
    SG_ SWI_IGK : 0|1@1+ (1.0,0.0) [0.0|1.0] ""  _4WD,ABS,ACU,AHLS,CUBIS,DI_BOX,ECS,EPB,ESC,IBOX,LDWS_LKAS,MDPS,REA,SAS,SCC,TCU
    SG_ F_N_ENG : 1|1@1+ (1.0,0.0) [0.0|1.0] ""  _4WD,ACU,AFLS,CLU,CUBIS,DATC,ECS,EPB,ESC,IBOX,MDPS,SCC,TCU
    SG_ ACK_TCS : 2|1@1+ (1.0,0.0) [0.0|1.0] ""  ESC,IBOX
    SG_ PUC_STAT : 3|1@1+ (1.0,0.0) [0.0|1.0] ""  _4WD,CLU,DATC,IBOX,TCU
    SG_ TQ_COR_STAT : 4|2@1+ (1.0,0.0) [0.0|3.0] ""  _4WD,ESC,IBOX,TCU
    SG_ RLY_AC : 6|1@1+ (1.0,0.0) [0.0|1.0] ""  DATC,IBOX,TCU
    SG_ F_SUB_TQI : 7|1@1+ (1.0,0.0) [0.0|1.0] ""  _4WD,ECS,EPB,ESC,IBOX,TCU
    SG_ TQI_ACOR : 8|8@1+ (0.390625,0.0) [0.0|99.6094] "%"  _4WD,EPB,ESC,IBOX,TCU
    SG_ N : 16|16@1+ (0.25,0.0) [0.0|16383.75] "rpm"  _4WD,ACU,AFLS,CLU,CUBIS,DATC,ECS,EPB,ESC,FPCM,IBOX,MDPS,SCC,TCU
    SG_ TQI : 32|8@1+ (0.390625,0.0) [0.0|99.6094] "%"  _4WD,ECS,EPB,ESC,IBOX,TCU
    SG_ TQFR : 40|8@1+ (0.390625,0.0) [0.0|99.6094] "%"  _4WD,EPB,ESC,IBOX,TCU
    SG_ VS : 48|8@1+ (1.0,0.0) [0.0|254.0] "km/h"  _4WD,AAF,ACU,AHLS,BCM,CLU,DATC,ECS,EPB,IBOX,LCA,LDWS_LKAS,LVR,MDPS,ODS,SCC,SMK,SPAS,TCU,TPMS
    SG_ RATIO_TQI_BAS_MAX_STND : 56|8@1+ (0.0078,0.0) [0.0|2.0] ""  _4WD,IBOX,TCU

BO_ 809 EMS12: 8 EMS
    SG_ CONF_TCU m1 : 0|6@1+ (1.0,0.0) [0.0|63.0] ""  _4WD,ACU,BCM,CLU,DATC,EPB,ESC,IBOX,LCA,SMK
    SG_ CAN_VERS m0 : 0|6@1+ (1.0,0.0) [0.0|7.7] ""  _4WD,ABS,ESC,IBOX
    SG_ TQ_STND m3 : 0|6@1+ (10.0,0.0) [0.0|630.0] "Nm"  _4WD,DATC,ECS,EPB,ESC,FATC,IBOX
    SG_ OBD_FRF_ACK m2 : 0|6@1+ (1.0,0.0) [0.0|63.0] ""  _4WD,ESC,IBOX
    SG_ MUL_CODE M : 6|2@1+ (1.0,0.0) [0.0|3.0] ""  _4WD,ABS,ACU,BCM,CLU,DATC,ECS,EPB,ESC,IBOX,LCA,SMK,TCU
    SG_ TEMP_ENG : 8|8@1+ (0.75,-48.0) [-48.0|143.25] "deg"  _4WD,BCM,CLU,DATC,EPB,ESC,IBOX,SMK,TCU
    SG_ MAF_FAC_ALTI_MMV : 16|8@1+ (0.00781,0.0) [0.0|1.99155] ""  IBOX,TCU
    SG_ VB_OFF_ACT : 24|1@1+ (1.0,0.0) [0.0|1.0] ""  IBOX,TCU
    SG_ ACK_ES : 25|1@1+ (1.0,0.0) [0.0|1.0] ""  _4WD,ACU,IBOX
    SG_ CONF_MIL_FMY : 26|3@1+ (1.0,0.0) [0.0|7.0] ""  ESC,IBOX,TCU
    SG_ OD_OFF_REQ : 29|1@1+ (1.0,0.0) [0.0|1.0] ""  IBOX,TCU
    SG_ ACC_ACT : 30|1@1+ (1.0,0.0) [0.0|1.0] ""  _4WD,ABS,CLU,ESC,IAP,IBOX,SCC,TCU
    SG_ CLU_ACK : 31|1@1+ (1.0,0.0) [0.0|1.0] ""  _4WD,EPB,ESC,IBOX
    SG_ BRAKE_ACT : 32|2@1+ (1.0,0.0) [0.0|3.0] ""  _4WD,ABS,ACU,AFLS,CLU,DATC,ECS,EPB,ESC,IBOX,LDWS_LKAS,TCU
    SG_ ENG_CHR : 34|4@1+ (1.0,0.0) [0.0|15.0] ""  _4WD,ABS,ACU,CLU,DATC,EPB,ESC,FATC,IBOX,SCC,SMK,TCU
    SG_ GP_CTL : 38|2@1+ (1.0,0.0) [0.0|3.0] ""  IBOX
    SG_ TPS : 40|8@1+ (0.4694836,-15.0234742) [-15.0234742|104.6948357] "%"  _4WD,ABS,ACU,CLU,DATC,ECS,EPB,ESC,IBOX,TCU
    SG_ PV_AV_CAN : 48|8@1+ (0.3906,0.0) [0.0|99.603] "%"  _4WD,AAF,ABS,ACU,AFLS,CLU,DATC,EPB,ESC,IAP,IBOX,LDWS_LKAS,SCC,TCU
    SG_ ENG_VOL : 56|8@1+ (0.1,0.0) [0.0|25.5] "liter"  _4WD,ABS,ACU,BCM,CLU,DATC,EPB,ESC,IBOX,LDWS_LKAS,SCC,SMK

BO_ 848 FATC: 8 XXX
    SG_ CR_Fatc_TqAcnOut : 0|8@1+ (0.2,0) [0|50.8] "Nm" XXX
    SG_ CF_Fatc_AcnRqSwi : 8|1@1+ (1,0) [0|1] "" XXX
    SG_ CF_Fatc_AcnCltEnRq : 9|1@1+ (1,0) [0|1] "" XXX
    SG_ CF_Fatc_EcvFlt : 10|1@1+ (1,0) [0|1] "" XXX
    SG_ CF_Fatc_BlwrOn : 11|1@1+ (1,0) [0|1] "" XXX
    SG_ CF_FATC_Iden : 12|2@1+ (1,0) [0|3] "" XXX
    SG_ CF_Fatc_BlwrMax : 14|1@1+ (1,0) [0|1] "" XXX
    SG_ CF_Fatc_EngStartReq : 15|1@1+ (1,0) [0|1] "" XXX
    SG_ CF_Fatc_IsgStopReq : 16|1@1+ (1,0) [0|1] "" XXX
    SG_ CF_Fatc_CtrInf : 17|3@1+ (1,0) [0|7] "" XXX
    SG_ CF_Fatc_MsgCnt : 20|4@1+ (1,0) [0|15] "" XXX
    SG_ CR_Fatc_OutTemp : 24|8@1+ (0.5,-40) [-40|60] "" XXX
    SG_ CR_Fatc_OutTempSns : 32|8@1+ (0.5,-40) [-40|60] "" XXX
    SG_ CF_Fatc_Compload : 40|3@1+ (1,0) [0|7] "" XXX
    SG_ CF_Fatc_ActiveEco : 43|1@1+ (1,0) [0|1] "" XXX
    SG_ CF_Fatc_AutoActivation : 44|1@1+ (1,0) [0|1] "" XXX
    SG_ CF_Fatc_DefSw : 45|1@1+ (1,0) [0|1] "" XXX
    SG_ CF_Fatc_PtcRlyStat : 46|1@1+ (1,0) [0|1] "" XXX
    SG_ CF_Fatc_ChkSum : 56|8@1+ (1,0) [0|255] "" XXX

BO_ 880 TCU3: 8 XXX
    SG_ N_TGT_LUP : 0|8@1+ (10,500) [500|3040] "rpm" XXX
    SG_ SLOPE_TCU : 8|6@1+ (0.5,-16) [-16|15.5] "%" XXX
    SG_ CF_Tcu_InhCda : 14|1@1+ (1,0) [0|1] "" XXX
    SG_ CF_Tcu_IsgInhib : 15|1@1+ (1,0) [0|1] "" XXX
    SG_ CF_Tcu_BkeOnReq : 16|2@1+ (1,0) [0|3] "" XXX
    SG_ CF_Tcu_NCStat : 18|2@1+ (1,0) [0|3] "" XXX
    SG_ CF_Tcu_TarGr : 20|4@1+ (1,0) [0|15] "" XXX
    SG_ CF_Tcu_ShfPatt : 24|4@1+ (1,0) [0|15] "" XXX
    SG_ CF_Tcu_InhVis : 28|1@1+ (1,0) [0|1] "" XXX
    SG_ CF_Tcu_PRelReq : 29|1@1+ (1,0) [0|1] "" XXX
    SG_ CF_Tcu_ITPhase : 30|1@1+ (1,0) [0|1] "" XXX
    SG_ CF_Tcu_ActEcoRdy : 31|1@1+ (1,0) [0|1] "" XXX
    SG_ CF_Tcu_TqGrdLim : 32|8@1+ (10,0) [0|2540] "Nm/s" XXX
    SG_ CR_Tcu_IsgTgtRPM : 40|8@1+ (20,0) [0|3500] "rpm" XXX
    SG_ TQI_TCU_INC : 48|8@1+ (0.390625,0) [0|99.6094] "%" XXX
    SG_ CF_Tcu_SbwPInfo : 56|1@1+ (1,0) [0|1] "" XXX
    SG_ CF_Tcu_SptRdy : 57|1@1+ (1,0) [0|1] "" XXX
    SG_ CF_Tcu_Alive3 : 58|2@1+ (1,0) [0|3] "" XXX
    SG_ CF_Tcu_ChkSum3 : 60|4@1+ (1,0) [0|15] "" XXX

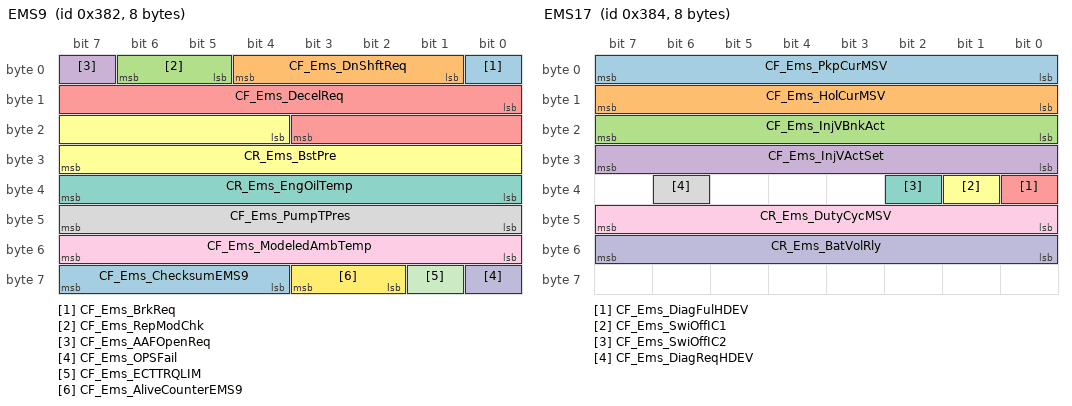
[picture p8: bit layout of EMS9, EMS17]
BO_ 898 EMS9: 8 XXX
    SG_ CF_Ems_BrkReq : 0|1@1+ (1,0) [0|1] "" XXX
    SG_ CF_Ems_DnShftReq : 1|4@1+ (1,0) [0|14] "" XXX
    SG_ CF_Ems_RepModChk : 5|2@1+ (1,0) [0|3] "" XXX
    SG_ CF_Ems_AAFOpenReq : 7|1@1+ (1,0) [0|1] "" XXX
    SG_ CF_Ems_DecelReq : 8|12@1+ (0.001,-4.094) [-4.094|0] "m/s^2" XXX
    SG_ CR_Ems_BstPre : 20|12@1+ (1.322,0) [0|4094] "hPa" XXX
    SG_ CR_Ems_EngOilTemp : 32|8@1+ (0.75,-40) [0|254] "" XXX
    SG_ CF_Ems_PumpTPres : 40|8@1+ (3.13725,0) [0|800] "kPa" XXX
    SG_ CF_Ems_ModeledAmbTemp : 48|8@1+ (0.5,-41) [-40|60] "" XXX
    SG_ CF_Ems_OPSFail : 56|1@1+ (1,0) [0|1] "" XXX
    SG_ CF_Ems_ECTTRQLIM : 57|1@1+ (1,0) [0|1] "" XXX
    SG_ CF_Ems_AliveCounterEMS9 : 58|2@1+ (1,0) [0|3] "" XXX
    SG_ CF_Ems_ChecksumEMS9 : 60|4@1+ (1,0) [0|15] "" XXX

BO_ 900 EMS17: 8 EMS
    SG_ CF_Ems_PkpCurMSV : 0|8@1+ (1.0,0.0) [0.0|255.0] ""  DI_BOX
    SG_ CF_Ems_HolCurMSV : 8|8@1+ (1.0,0.0) [0.0|255.0] ""  DI_BOX
    SG_ CF_Ems_InjVBnkAct : 16|8@1+ (1.0,0.0) [0.0|255.0] ""  DI_BOX
    SG_ CF_Ems_InjVActSet : 24|8@1+ (1.0,0.0) [0.0|255.0] ""  DI_BOX
    SG_ CF_Ems_DiagFulHDEV : 32|1@1+ (1.0,0.0) [0.0|1.0] ""  DI_BOX
    SG_ CF_Ems_SwiOffIC1 : 33|1@1+ (1.0,0.0) [0.0|1.0] ""  DI_BOX
    SG_ CF_Ems_SwiOffIC2 : 34|1@1+ (1.0,0.0) [0.0|1.0] ""  DI_BOX
    SG_ CF_Ems_DiagReqHDEV : 38|1@1+ (1.0,0.0) [0.0|1.0] ""  DI_BOX
    SG_ CR_Ems_DutyCycMSV : 40|8@1+ (0.3921568627,0.0) [0.0|100.0] "%"  DI_BOX
    SG_ CR_Ems_BatVolRly : 48|8@1+ (0.1,0.0) [0.0|25.5] "V"  DI_BOX

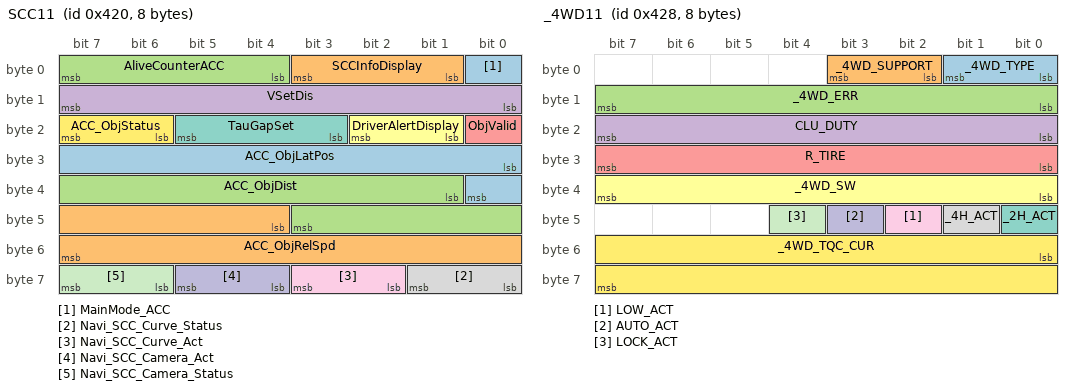
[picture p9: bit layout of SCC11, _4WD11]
BO_ 1056 SCC11: 8 SCC
    SG_ MainMode_ACC : 0|1@1+ (1,0) [0|1] "" CLU,EMS,ESC
    SG_ SCCInfoDisplay : 1|3@1+ (1,0) [0|7] "" CLU,ESC
    SG_ AliveCounterACC : 4|4@1+ (1,0) [0|15] "" CLU,EMS,ESC,TCU
    SG_ VSetDis : 8|8@1+ (1,0) [0|255] "km/h or MPH" CLU,ESC,TCU
    SG_ ObjValid : 16|1@1+ (1,0) [0|1] "" CLU,ESC,TCU
    SG_ DriverAlertDisplay : 17|2@1+ (1,0) [0|3] "" CLU,ESC
    SG_ TauGapSet : 19|3@1+ (1,0) [0|7] "" CLU,ESC,TCU
    SG_ Navi_SCC_Curve_Status : 56|2@1+ (1,0) [0|3] "" CLU
    SG_ Navi_SCC_Curve_Act : 58|2@1+ (1,0) [0|3] "" CLU
    SG_ Navi_SCC_Camera_Act : 60|2@1+ (1,0) [0|3] "" CLU
    SG_ Navi_SCC_Camera_Status : 62|2@1+ (1,0) [0|3] "" CLU
    SG_ ACC_ObjStatus : 22|2@1+ (1,0) [0|3] "" ABS,ESC
    SG_ ACC_ObjLatPos : 24|9@1+ (0.1,-20) [-20|31.1] "m" ABS,ESC
    SG_ ACC_ObjRelSpd : 44|12@1+ (0.1,-170) [-170|239.5] "m/s" ABS,ESC
    SG_ ACC_ObjDist : 33|11@1+ (0.1,0) [0|204.7] "m" ABS,ESC

BO_ 1064 _4WD11: 8 _4WD
    SG_ _4WD_TYPE : 0|2@1+ (1.0,0.0) [0.0|3.0] ""  ACU,ESC,TPMS
    SG_ _4WD_SUPPORT : 2|2@1+ (1.0,0.0) [0.0|3.0] ""  ABS,ESC,TPMS
    SG_ _4WD_ERR : 8|8@1+ (1.0,0.0) [0.0|255.0] ""  CLU,ESC
    SG_ CLU_DUTY : 16|8@1+ (1.0,0.0) [0.0|64.0] "%"  ABS,ESC
    SG_ R_TIRE : 24|8@1+ (1.0,200.0) [200.0|455.0] "mm"  ABS,ESC,TPMS
    SG_ _4WD_SW : 32|8@1+ (1.0,0.0) [0.0|9.9] ""  ESC
    SG_ _2H_ACT : 40|1@1+ (1.0,0.0) [0.0|1.0] ""  ABS,ESC
    SG_ _4H_ACT : 41|1@1+ (1.0,0.0) [0.0|1.0] ""  ABS,CLU,ESC,TPMS
    SG_ LOW_ACT : 42|1@1+ (1.0,0.0) [0.0|1.0] ""  ABS,ESC,TCU,TPMS
    SG_ AUTO_ACT : 43|1@1+ (1.0,0.0) [0.0|1.0] ""  ABS,ESC,TPMS
    SG_ LOCK_ACT : 44|1@1+ (1.0,0.0) [0.0|1.0] ""  ABS,CLU,ESC,TPMS
    SG_ _4WD_TQC_CUR : 48|16@1+ (1.0,0.0) [0.0|65535.0] "Nm"  ABS,ESC

BO_ 1065 _4WD12: 8 _4WD
    SG_ Ster_Pos : 0|16@1+ (1.0,-600.0) [-600.0|600.0] "Deg"  ESC
    SG_ FRSS : 16|8@1+ (1.0,0.0) [0.0|254.0] "km/h"  ESC
    SG_ FLSS : 24|8@1+ (1.0,0.0) [0.0|254.0] "km/h"  ESC
    SG_ RRSS : 32|8@1+ (1.0,0.0) [0.0|254.0] "km/h"  ESC
    SG_ RLSS : 40|8@1+ (1.0,0.0) [0.0|254.0] "km/h"  ESC
    SG_ CLU_PRES : 48|16@1+ (0.0625,-50.0) [-50.0|50.0] "Bar"  ESC

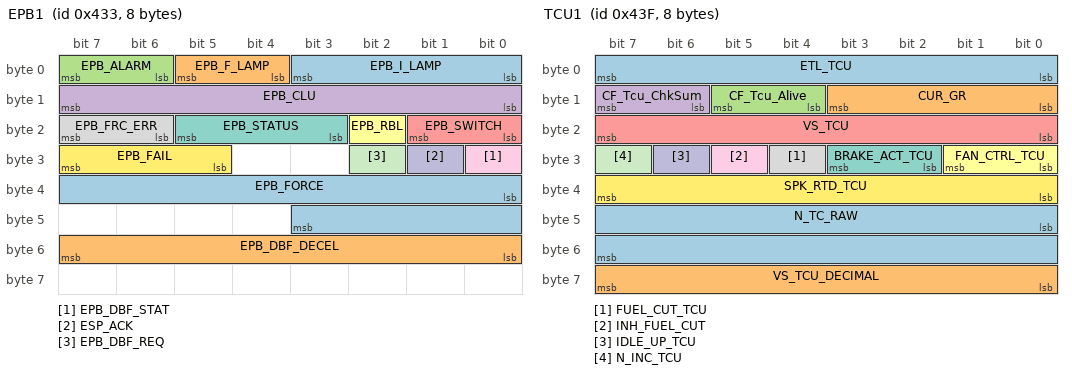
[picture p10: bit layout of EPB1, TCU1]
BO_ 1075 EPB1: 8 XXX
    SG_ EPB_I_LAMP : 0|4@1+ (1,0) [0|15] "" XXX
    SG_ EPB_F_LAMP : 4|2@1+ (1,0) [0|3] "" XXX
    SG_ EPB_ALARM : 6|2@1+ (1,0) [0|3] "" XXX
    SG_ EPB_CLU : 8|8@1+ (1,0) [0|255] "" XXX
    SG_ EPB_SWITCH : 16|2@1+ (1,0) [0|3] "" XXX
    SG_ EPB_RBL : 18|1@1+ (1,0) [0|1] "" XXX
    SG_ EPB_STATUS : 19|3@1+ (1,0) [0|7] "" XXX
    SG_ EPB_FRC_ERR : 22|2@1+ (1,0) [0|3] "" XXX
    SG_ EPB_DBF_STAT : 24|1@1+ (1,0) [0|1] "" XXX
    SG_ ESP_ACK : 25|1@1+ (1,0) [0|1] "" XXX
    SG_ EPB_DBF_REQ : 26|1@1+ (1,0) [0|1] "" XXX
    SG_ EPB_FAIL : 29|3@1+ (1,0) [0|7] "" XXX
    SG_ EPB_FORCE : 32|12@1+ (1,-1000) [-1000|3000] "" XXX
    SG_ EPB_DBF_DECEL : 48|8@1+ (0.01,0) [0|2.54] "g" XXX

BO_ 1087 TCU1: 8 XXX
    SG_ ETL_TCU : 0|8@1+ (2,0) [0|508] "Nm" XXX
    SG_ CUR_GR : 8|4@1+ (1,0) [0|15] "" XXX
    SG_ CF_Tcu_Alive : 12|2@1+ (1,0) [0|3] "" XXX
    SG_ CF_Tcu_ChkSum : 14|2@1+ (1,0) [0|3] "" XXX
    SG_ VS_TCU : 16|8@1+ (1,0) [0|254] "km/h" XXX
    SG_ FAN_CTRL_TCU : 24|2@1+ (1,0) [0|3] "" XXX
    SG_ BRAKE_ACT_TCU : 26|2@1+ (1,0) [0|3] "" XXX
    SG_ FUEL_CUT_TCU : 28|1@1+ (1,0) [0|1] "" XXX
    SG_ INH_FUEL_CUT : 29|1@1+ (1,0) [0|1] "" XXX
    SG_ IDLE_UP_TCU : 30|1@1+ (1,0) [0|1] "" XXX
    SG_ N_INC_TCU : 31|1@1+ (1,0) [0|1] "" XXX
    SG_ SPK_RTD_TCU : 32|8@1+ (0.375,-23.625) [-15|15] "" XXX
    SG_ N_TC_RAW : 40|16@1+ (0.25,0) [0|16383.5] "rpm" XXX
    SG_ VS_TCU_DECIMAL : 56|8@1+ (0.0078125,0) [0|0.992188] "km/h" XXX

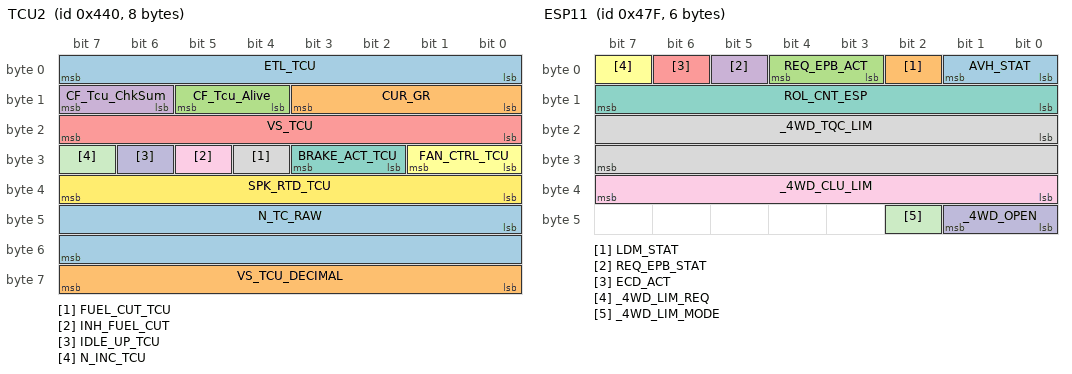
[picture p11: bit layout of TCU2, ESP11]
BO_ 1088 TCU2: 8 XXX
    SG_ ETL_TCU : 0|8@1+ (2,0) [0|508] "Nm" XXX
    SG_ CUR_GR : 8|4@1+ (1,0) [0|15] "" XXX
    SG_ CF_Tcu_Alive : 12|2@1+ (1,0) [0|3] "" XXX
    SG_ CF_Tcu_ChkSum : 14|2@1+ (1,0) [0|3] "" XXX
    SG_ VS_TCU : 16|8@1+ (1,0) [0|254] "km/h" XXX
    SG_ FAN_CTRL_TCU : 24|2@1+ (1,0) [0|3] "" XXX
    SG_ BRAKE_ACT_TCU : 26|2@1+ (1,0) [0|3] "" XXX
    SG_ FUEL_CUT_TCU : 28|1@1+ (1,0) [0|1] "" XXX
    SG_ INH_FUEL_CUT : 29|1@1+ (1,0) [0|1] "" XXX
    SG_ IDLE_UP_TCU : 30|1@1+ (1,0) [0|1] "" XXX
    SG_ N_INC_TCU : 31|1@1+ (1,0) [0|1] "" XXX
    SG_ SPK_RTD_TCU : 32|8@1+ (0.375,-23.625) [-15|15] "" XXX
    SG_ N_TC_RAW : 40|16@1+ (0.25,0) [0|16383.5] "rpm" XXX
    SG_ VS_TCU_DECIMAL : 56|8@1+ (0.0078125,0) [0|0.992188] "km/h" XXX

BO_ 1151 ESP11: 6 ESC
    SG_ AVH_STAT : 0|2@1+ (1.0,0.0) [0.0|3.0] ""  EMS,EPB,TCU
    SG_ LDM_STAT : 2|1@1+ (1.0,0.0) [0.0|1.0] ""  EPB,TCU
    SG_ REQ_EPB_ACT : 3|2@1+ (1.0,0.0) [0.0|3.0] ""  EPB,TCU
    SG_ REQ_EPB_STAT : 5|1@1+ (1.0,0.0) [0.0|1.0] ""  EPB
    SG_ ECD_ACT : 6|1@1+ (1.0,0.0) [0.0|1.0] ""  EPB
    SG_ _4WD_LIM_REQ : 7|1@1+ (1.0,0.0) [0.0|1.0] ""  _4WD,EMS
    SG_ ROL_CNT_ESP : 8|8@1+ (1.0,0.0) [0.0|255.0] ""  EPB,TCU
    SG_ _4WD_TQC_LIM : 16|16@1+ (1.0,0.0) [0.0|65535.0] "Nm"  _4WD,EMS
    SG_ _4WD_CLU_LIM : 32|8@1+ (0.390625,0.0) [0.0|99.609375] "%"  _4WD,EMS
    SG_ _4WD_OPEN : 40|2@1+ (1.0,0.0) [0.0|3.0] ""  _4WD,EMS
    SG_ _4WD_LIM_MODE : 42|1@1+ (1.0,0.0) [0.0|1.0] ""  _4WD

BO_ 1200 WHL_SPD: 8 XXX
    SG_ WHL_SPD_FL : 0|14@1+ (0.03125,0) [0|511.969] "km/h" XXX
    SG_ WHL_SPD_FR : 16|14@1+ (0.03125,0) [0|511.969] "km/h" XXX
    SG_ WHL_SPD_RL : 32|14@1+ (0.03125,0) [0|511.969] "km/h" XXX
    SG_ WHL_SPD_RR : 48|14@1+ (0.03125,0) [0|511.969] "km/h" XXX

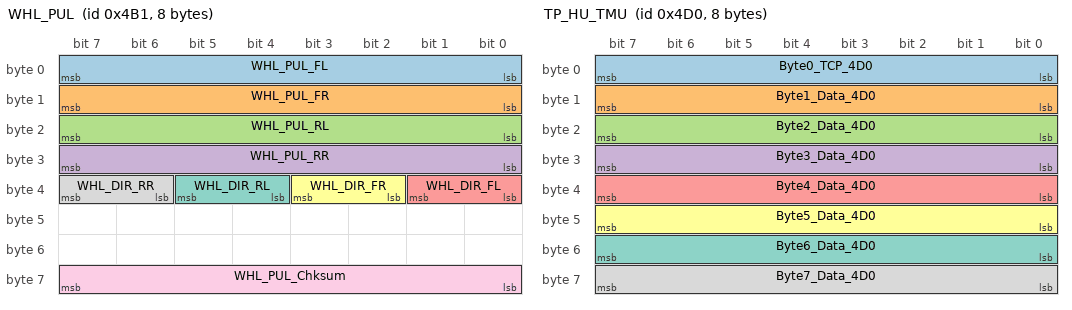
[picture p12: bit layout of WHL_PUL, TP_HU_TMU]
BO_ 1201 WHL_PUL: 8 XXX
    SG_ WHL_PUL_FL : 0|8@1+ (0.5,0) [0|127.5] "pulse count" XXX
    SG_ WHL_PUL_FR : 8|8@1+ (0.5,0) [0|127.5] "pulse count" XXX
    SG_ WHL_PUL_RL : 16|8@1+ (0.5,0) [0|127.5] "pulse count" XXX
    SG_ WHL_PUL_RR : 24|8@1+ (0.5,0) [0|127.5] "pulse count" XXX
    SG_ WHL_DIR_FL : 32|2@1+ (1,0) [0|3] "" XXX
    SG_ WHL_DIR_FR : 34|2@1+ (1,0) [0|3] "" XXX
    SG_ WHL_DIR_RL : 36|2@1+ (1,0) [0|3] "" XXX
    SG_ WHL_DIR_RR : 38|2@1+ (1,0) [0|3] "" XXX
    SG_ WHL_PUL_Chksum : 56|8@1+ (1,0) [0|255] "" XXX

BO_ 1232 TP_HU_TMU: 8 H_U
    SG_ Byte0_TCP_4D0 : 7|8@0+ (1,0) [0|0] ""  TMU
    SG_ Byte1_Data_4D0 : 15|8@0+ (1,0) [0|0] ""  TMU
    SG_ Byte2_Data_4D0 : 23|8@0+ (1,0) [0|0] ""  TMU
    SG_ Byte3_Data_4D0 : 31|8@0+ (1,0) [0|0] ""  TMU
    SG_ Byte4_Data_4D0 : 39|8@0+ (1,0) [0|0] ""  TMU
    SG_ Byte5_Data_4D0 : 47|8@0+ (1,0) [0|0] ""  TMU
    SG_ Byte6_Data_4D0 : 55|8@0+ (1,0) [0|0] ""  TMU
    SG_ Byte7_Data_4D0 : 63|8@0+ (1,0) [0|0] ""  TMU

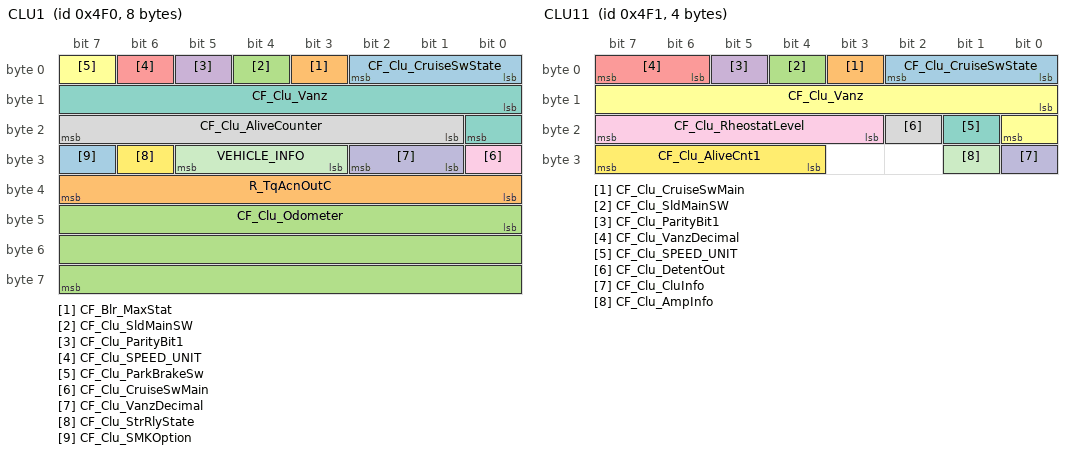
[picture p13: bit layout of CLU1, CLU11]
BO_ 1264 CLU1: 8 XXX
    SG_ CF_Clu_CruiseSwState : 0|3@1+ (1,0) [0|7] "" XXX
    SG_ CF_Blr_MaxStat : 3|1@1+ (1,0) [0|1] "" XXX
    SG_ CF_Clu_SldMainSW : 4|1@1+ (1,0) [0|1] "" XXX
    SG_ CF_Clu_ParityBit1 : 5|1@1+ (1,0) [0|1] "pulse count" XXX
    SG_ CF_Clu_SPEED_UNIT : 6|1@1+ (1,0) [0|1] "" XXX
    SG_ CF_Clu_ParkBrakeSw : 7|1@1+ (1,0) [0|1] "" XXX
    SG_ CF_Clu_Vanz : 8|9@1+ (0.5,0) [0|255.5] "km/h or MPH" XXX
    SG_ CF_Clu_AliveCounter : 17|7@1+ (1,0) [0|127] "" XXX
    SG_ CF_Clu_CruiseSwMain : 24|1@1+ (1,0) [0|1] "" XXX
    SG_ CF_Clu_VanzDecimal : 25|2@1+ (1,0) [0|0.375] "" XXX
    SG_ VEHICLE_INFO : 27|3@1+ (1,0) [0|7] "" XXX
    SG_ CF_Clu_StrRlyState : 30|1@1+ (1,0) [0|1] "" XXX
    SG_ CF_Clu_SMKOption : 31|1@1+ (1,0) [0|1] "" XXX
    SG_ R_TqAcnOutC : 32|8@1+ (1,0) [0|51] "Nm" XXX
    SG_ CF_Clu_Odometer : 40|24@1+ (0.1,0) [0|1.67772e+006] "km" XXX

BO_ 1265 CLU11: 4 CLU
    SG_ CF_Clu_CruiseSwState : 0|3@1+ (1.0,0.0) [0.0|7.0] ""  EMS,LDWS_LKAS,SCC
    SG_ CF_Clu_CruiseSwMain : 3|1@1+ (1.0,0.0) [0.0|1.0] ""  EMS,LDWS_LKAS,SCC
    SG_ CF_Clu_SldMainSW : 4|1@1+ (1.0,0.0) [0.0|1.0] ""  EMS
    SG_ CF_Clu_ParityBit1 : 5|1@1+ (1.0,0.0) [0.0|1.0] "pulse count"  EMS
    SG_ CF_Clu_VanzDecimal : 6|2@1+ (0.125,0.0) [0.0|0.375] ""  EMS
    SG_ CF_Clu_Vanz : 8|9@1+ (0.5,0.0) [0.0|255.5] "km/h or MPH"  BCM,CUBIS,EMS,IBOX,LDWS_LKAS,MDPS,SCC
    SG_ CF_Clu_SPEED_UNIT : 17|1@1+ (1.0,0.0) [0.0|1.0] ""  BCM,CUBIS,EMS,IBOX,LDWS_LKAS,MDPS,SCC
    SG_ CF_Clu_DetentOut : 18|1@1+ (1.0,0.0) [0.0|1.0] ""  AVM,BCM,LCA,PGS,SPAS
    SG_ CF_Clu_RheostatLevel : 19|5@1+ (1.0,0.0) [0.0|31.0] ""  AVM,BCM,LCA,PGS,SPAS
    SG_ CF_Clu_CluInfo : 24|1@1+ (1.0,0.0) [0.0|1.0] ""  BCM
    SG_ CF_Clu_AmpInfo : 25|1@1+ (1.0,0.0) [0.0|1.0] ""  BCM
    SG_ CF_Clu_AliveCnt1 : 28|4@1+ (1.0,0.0) [0.0|15.0] ""  AHLS,EMS,EPB,LDWS_LKAS,MDPS,SCC

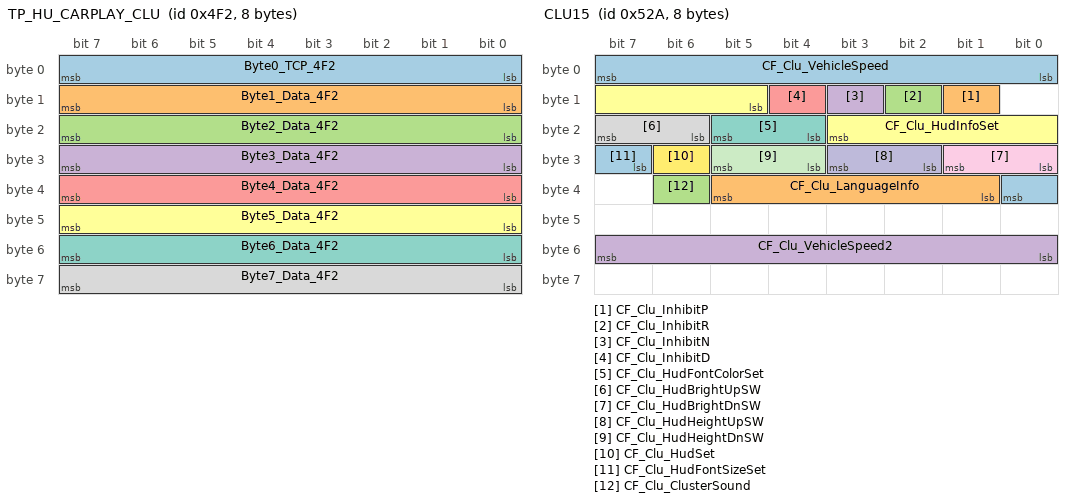
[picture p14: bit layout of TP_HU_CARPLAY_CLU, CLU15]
BO_ 1266 TP_HU_CARPLAY_CLU: 8 H_U
    SG_ Byte0_TCP_4F2 : 7|8@0+ (1,0) [0|0] ""  CLU
    SG_ Byte1_Data_4F2 : 15|8@0+ (1,0) [0|0] ""  CLU
    SG_ Byte2_Data_4F2 : 23|8@0+ (1,0) [0|0] ""  CLU
    SG_ Byte3_Data_4F2 : 31|8@0+ (1,0) [0|0] ""  CLU
    SG_ Byte4_Data_4F2 : 39|8@0+ (1,0) [0|0] ""  CLU
    SG_ Byte5_Data_4F2 : 47|8@0+ (1,0) [0|0] ""  CLU
    SG_ Byte6_Data_4F2 : 55|8@0+ (1,0) [0|0] ""  CLU
    SG_ Byte7_Data_4F2 : 63|8@0+ (1,0) [0|0] ""  CLU

BO_ 1312 CGW3: 8 BCM
    SG_ CR_Photosensor_LH : 0|8@1+ (78.125,0.0) [0.0|20000.0] ""  DATC,DATC
    SG_ CR_Photosensor_RH : 10|8@1+ (78.125,0.0) [0.0|20000.0] ""  DATC,DATC
    SG_ CF_Hoodsw_memory : 22|2@1+ (1.0,0.0) [0.0|3.0] ""  EMS,EMS
    SG_ C_MirOutTempSns : 24|8@1+ (0.5,-40.5) [-40.0|60.0] "deg"  AAF,CLU,DATC,EMS,SPAS,AAF,DATC,EMS,SPAS

BO_ 1322 CLU15: 8 CLU
    SG_ CF_Clu_VehicleSpeed : 0|8@1+ (1.0,0.0) [0.0|255.0] ""  BCM
    SG_ CF_Clu_InhibitP : 9|1@1+ (1.0,0.0) [0.0|1.0] ""  BCM
    SG_ CF_Clu_InhibitR : 10|1@1+ (1.0,0.0) [0.0|1.0] ""  BCM
    SG_ CF_Clu_InhibitN : 11|1@1+ (1.0,0.0) [0.0|1.0] ""  BCM
    SG_ CF_Clu_InhibitD : 12|1@1+ (1.0,0.0) [0.0|1.0] ""  BCM
    SG_ CF_Clu_HudInfoSet : 13|7@1+ (1.0,0.0) [0.0|127.0] ""  HUD
    SG_ CF_Clu_HudFontColorSet : 20|2@1+ (1.0,0.0) [0.0|3.0] ""  HUD
    SG_ CF_Clu_HudBrightUpSW : 22|2@1+ (1.0,0.0) [0.0|3.0] ""  HUD
    SG_ CF_Clu_HudBrightDnSW : 24|2@1+ (1.0,0.0) [0.0|3.0] ""  HUD
    SG_ CF_Clu_HudHeightUpSW : 26|2@1+ (1.0,0.0) [0.0|3.0] ""  HUD
    SG_ CF_Clu_HudHeightDnSW : 28|2@1+ (1.0,0.0) [0.0|3.0] ""  HUD
    SG_ CF_Clu_HudSet : 30|1@1+ (1.0,0.0) [0.0|1.0] ""  HUD
    SG_ CF_Clu_HudFontSizeSet : 31|2@1+ (1.0,0.0) [0.0|3.0] ""  HUD
    SG_ CF_Clu_LanguageInfo : 33|5@1+ (1.0,0.0) [0.0|31.0] ""  BCM,PGS
    SG_ CF_Clu_ClusterSound : 38|1@1- (1.0,0.0) [0.0|0.0] ""  BCM,CGW,FATC
    SG_ CF_Clu_VehicleSpeed2 : 48|8@1+ (1,0) [0|255] "" XXX

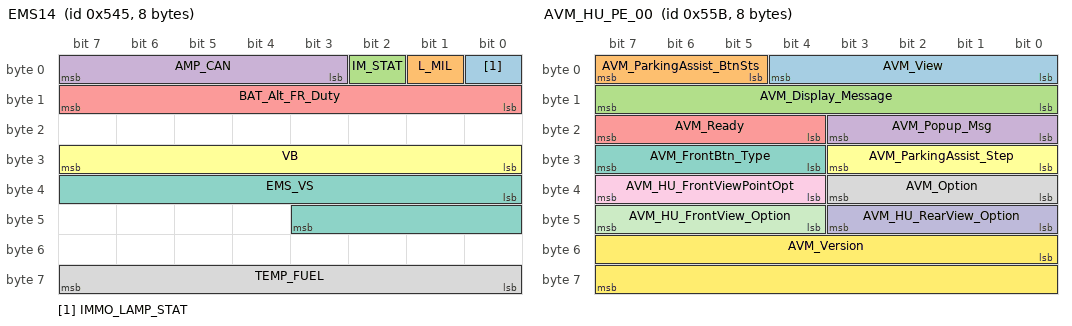
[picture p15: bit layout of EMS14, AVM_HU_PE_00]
BO_ 1349 EMS14: 8 EMS
    SG_ IMMO_LAMP_STAT : 0|1@1+ (1.0,0.0) [0.0|1.0] ""  CLU,IBOX
    SG_ L_MIL : 1|1@1+ (1.0,0.0) [0.0|1.0] ""  CLU,CUBIS,IBOX
    SG_ IM_STAT : 2|1@1+ (1.0,0.0) [0.0|1.0] ""  CLU,IBOX
    SG_ AMP_CAN : 3|5@1+ (10.731613,458.98) [458.98|791.660003] "mmHg"  CLU,IBOX,TCU,TPMS
    SG_ BAT_Alt_FR_Duty : 8|8@1+ (0.4,0.0) [0.0|100.0] "%"  CGW,CUBIS,IBOX,TMU
    SG_ VB : 24|8@1+ (0.1015625,0.0) [0.0|25.8984375] "V"  CLU,CUBIS,DATC,EPB,FPCM,IBOX
    SG_ EMS_VS : 32|12@1+ (0.0625,0.0) [0.0|255.875] "km/h"  CLU
    SG_ TEMP_FUEL : 56|8@1+ (0.75,-48.0) [-48.0|143.25] "deg"  FPCM

BO_ 1369 CGW4: 8 BCM
    SG_ CF_Gway_MemoryP1Cmd : 0|1@1+ (1.0,0.0) [0.0|1.0] ""  CLU
    SG_ CF_Gway_MemoryP2Cmd : 1|1@1+ (1.0,0.0) [0.0|1.0] ""  CLU
    SG_ CF_Gway_PBackP1Cmd : 2|1@1+ (1.0,0.0) [0.0|1.0] ""  CLU
    SG_ CF_Gway_PBackP2Cmd : 3|1@1+ (1.0,0.0) [0.0|1.0] ""  CLU
    SG_ CF_Gway_StrgWhlHeatedState : 4|1@1+ (1.0,0.0) [0.0|1.0] ""  CLU
    SG_ CF_Gway_PBackStopCmd : 5|1@1+ (1.0,0.0) [0.0|1.0] ""  CLU,HUD
    SG_ CF_Gway_StaticBendLhAct : 6|1@1+ (1.0,0.0) [0.0|1.0] ""  CLU
    SG_ CF_Gway_StaticBendRhAct : 7|1@1+ (1.0,0.0) [0.0|1.0] ""  CLU
    SG_ CF_Gway_DrvWdwStat : 8|1@1+ (1.0,0.0) [0.0|1.0] ""  CLU
    SG_ CF_Gway_RLWdwState : 9|1@1+ (1.0,0.0) [0.0|1.0] ""  CLU
    SG_ CF_Gway_RRWdwState : 10|1@1+ (1.0,0.0) [0.0|1.0] ""  CLU
    SG_ CF_Gway_AstWdwStat : 11|1@1+ (1.0,0.0) [0.0|1.0] ""  CLU
    SG_ CF_Gway_MemoryEnable : 12|1@1+ (1.0,0.0) [0.0|1.0] ""  CLU
    SG_ CF_Gway_PBACKStopCmd : 13|1@1+ (1.0,0.0) [0.0|1.0] ""  CLU
    SG_ CF_Gway_PBACKStop : 14|1@1+ (1.0,0.0) [0.0|1.0] ""  CLU,HUD
    SG_ CF_Gway_IMSBuzzer : 15|1@1+ (1.0,0.0) [0.0|1.0] ""  CLU
    SG_ CF_Gway_DrvSeatBeltInd : 36|2@1+ (1.0,0.0) [0.0|3.0] ""  CLU,Dummy
    SG_ CF_Gway_AstSeatBeltInd : 38|2@1+ (1.0,0.0) [0.0|3.0] ""  CLU
    SG_ CF_Gway_RCSeatBeltInd : 40|2@1+ (1.0,0.0) [0.0|3.0] ""  CLU
    SG_ CF_Gway_RLSeatBeltInd : 42|2@1+ (1.0,0.0) [0.0|3.0] ""  CLU
    SG_ CF_Gway_RRSeatBeltInd : 44|2@1+ (1.0,0.0) [0.0|3.0] ""  CLU
    SG_ CF_Gway_RrWiperHighSw : 46|1@1+ (1.0,0.0) [0.0|1.0] ""  CLU
    SG_ CF_Gway_RrWiperLowSw : 47|1@1+ (1.0,0.0) [0.0|1.0] ""  CLU

BO_ 1370 HU_AVM_PE_00: 8 CLU
    SG_ HU_AVM_Status : 0|2@1+ (1.0,0.0) [0.0|3.0] ""  AVM,PGS

BO_ 1371 AVM_HU_PE_00: 8 AVM
    SG_ AVM_View : 0|5@1+ (1.0,0.0) [0.0|31.0] ""  CLU
    SG_ AVM_ParkingAssist_BtnSts : 5|3@1+ (1.0,0.0) [0.0|7.0] ""  CLU
    SG_ AVM_Display_Message : 8|8@1+ (1.0,0.0) [0.0|255.0] ""  CLU
    SG_ AVM_Popup_Msg : 16|4@1+ (1.0,0.0) [0.0|15.0] ""  CLU
    SG_ AVM_Ready : 20|4@1+ (1.0,0.0) [0.0|15.0] ""  CLU
    SG_ AVM_ParkingAssist_Step : 24|4@1+ (1.0,0.0) [0.0|15.0] ""  CLU
    SG_ AVM_FrontBtn_Type : 28|4@1+ (1.0,0.0) [0.0|15.0] ""  CLU
    SG_ AVM_Option : 32|4@1+ (1.0,0.0) [0.0|15.0] ""  CLU
    SG_ AVM_HU_FrontViewPointOpt : 36|4@1+ (1.0,0.0) [0.0|15.0] ""  CLU
    SG_ AVM_HU_RearView_Option : 40|4@1+ (1.0,0.0) [0.0|15.0] ""  CLU
    SG_ AVM_HU_FrontView_Option : 44|4@1+ (1.0,0.0) [0.0|15.0] ""  CLU
    SG_ AVM_Version : 48|16@1+ (1.0,0.0) [0.0|65535.0] ""  CLU

BO_ 1407 HU_MON_PE_01: 8 CLU
    SG_ HU_Type : 0|8@1+ (1.0,0.0) [0.0|255.0] ""  AVM,PGS

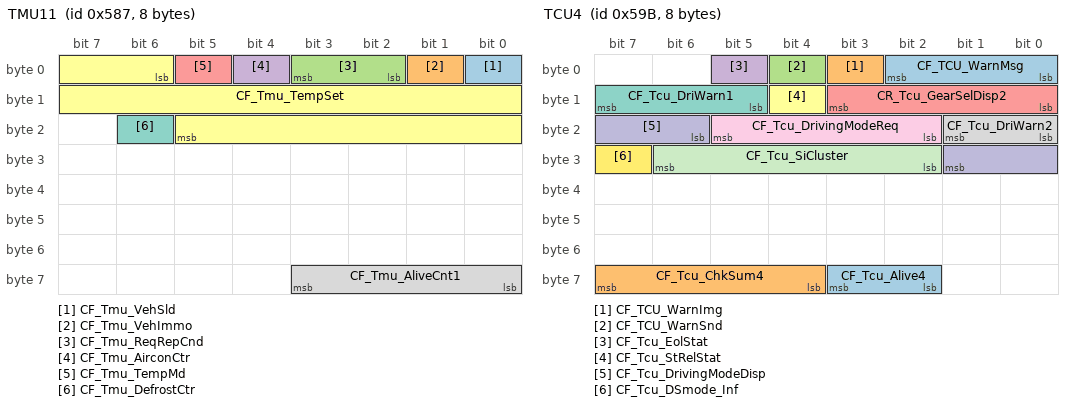
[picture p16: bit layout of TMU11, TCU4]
BO_ 1415 TMU11: 8 IBOX
    SG_ CF_Tmu_VehSld : 0|1@1+ (1.0,0.0) [0.0|1.0] ""  EMS
    SG_ CF_Tmu_VehImmo : 1|1@1+ (1.0,0.0) [0.0|1.0] ""  EMS
    SG_ CF_Tmu_ReqRepCnd : 2|2@1+ (1.0,0.0) [0.0|3.0] ""  EMS
    SG_ CF_Tmu_AirconCtr : 4|1@1+ (1.0,0.0) [0.0|1.0] ""  DATC
    SG_ CF_Tmu_TempMd : 5|1@1+ (1.0,0.0) [0.0|1.0] ""  DATC
    SG_ CF_Tmu_TempSet : 6|16@1+ (1.0,0.0) [0.0|20.0] ""  DATC
    SG_ CF_Tmu_DefrostCtr : 22|1@1+ (1.0,0.0) [0.0|1.0] ""  DATC,FATC
    SG_ CF_Tmu_AliveCnt1 : 56|4@1+ (1.0,0.0) [0.0|15.0] ""  EMS

BO_ 1419 LCA11: 8 LCA
    SG_ CF_Lca_Stat : 0|4@1+ (1.0,0.0) [0.0|15.0] ""  BCM,CLU
    SG_ CF_Rcta_Stat : 4|4@1+ (1.0,0.0) [0.0|15.0] ""  BCM,CLU
    SG_ CF_Lca_IndLeft : 8|2@1+ (1.0,0.0) [0.0|3.0] ""  BCM,CLU
    SG_ CF_Rcw_Stat : 10|4@1+ (1.0,0.0) [0.0|15.0] ""  BCM,CLU
    SG_ CF_RCW_Warning : 14|2@1+ (1.0,0.0) [0.0|3.0] ""  BCM,CLU
    SG_ CF_Lca_IndRight : 16|2@1+ (1.0,0.0) [0.0|3.0] ""  BCM,CLU
    SG_ CF_Lca_SndWan_Stat : 18|2@1+ (1.0,0.0) [0.0|3.0] ""  BCM,CLU
    SG_ CF_FR_SndWan : 20|1@1+ (1.0,0.0) [0.0|1.0] ""  BCM,CLU
    SG_ CF_FL_SndWan : 21|1@1+ (1.0,0.0) [0.0|1.0] ""  BCM,CLU
    SG_ CF_RR_SndWan : 22|1@1+ (1.0,0.0) [0.0|1.0] ""  BCM,CLU
    SG_ CF_RL_SndWan : 23|1@1+ (1.0,0.0) [0.0|1.0] ""  BCM,CLU
    SG_ CF_Lca_IndBriLeft : 24|8@1+ (1.0,0.0) [0.0|255.0] ""  BCM,CLU
    SG_ CF_Lca_IndBriRight : 32|8@1+ (1.0,0.0) [0.0|255.0] ""  BCM,CLU
    SG_ CF_RCTA_IndBriLeft : 40|8@1+ (1.0,0.0) [0.0|255.0] ""  BCM,CLU
    SG_ CF_RCTA_IndBriRight : 48|8@1+ (1.0,0.0) [0.0|255.0] ""  BCM,CLU
    SG_ CF_RCTA_IndLeft : 56|2@1+ (1.0,0.0) [0.0|3.0] ""  BCM,CLU
    SG_ CF_RCTA_IndRight : 58|2@1+ (1.0,0.0) [0.0|3.0] ""  BCM,CLU
    SG_ CF_SndWarnForClu : 60|1@1+ (1.0,0.0) [0.0|1.0] ""  CLU

BO_ 1435 TCU4: 8 XXX
    SG_ CF_TCU_WarnMsg : 0|3@1+ (1,0) [0|7] "" XXX
    SG_ CF_TCU_WarnImg : 3|1@1+ (1,0) [0|1] "" XXX
    SG_ CF_TCU_WarnSnd : 4|1@1+ (1,0) [0|1] "" XXX
    SG_ CF_Tcu_EolStat : 5|1@1+ (1,0) [0|1] "" XXX
    SG_ CR_Tcu_GearSelDisp2 : 8|4@1+ (1,0) [0|15] "" XXX
    SG_ CF_Tcu_StRelStat : 12|1@1+ (1,0) [0|1] "" XXX
    SG_ CF_Tcu_DriWarn1 : 13|3@1+ (1,0) [0|7] "" XXX
    SG_ CF_Tcu_DriWarn2 : 16|2@1+ (1,0) [0|3] "" XXX
    SG_ CF_Tcu_DrivingModeReq : 18|4@1+ (1,0) [0|0] "" XXX
    SG_ CF_Tcu_DrivingModeDisp : 22|4@1+ (1,0) [0|0] "" XXX
    SG_ CF_Tcu_SiCluster : 26|5@1+ (1,0) [0|0] "" XXX
    SG_ CF_Tcu_DSmode_Inf : 31|1@1+ (1,0) [0|1] "" XXX
    SG_ CF_Tcu_Alive4 : 58|2@1+ (1,0) [0|3] "" XXX
    SG_ CF_Tcu_ChkSum4 : 60|4@1+ (1,0) [0|15] "" XXX

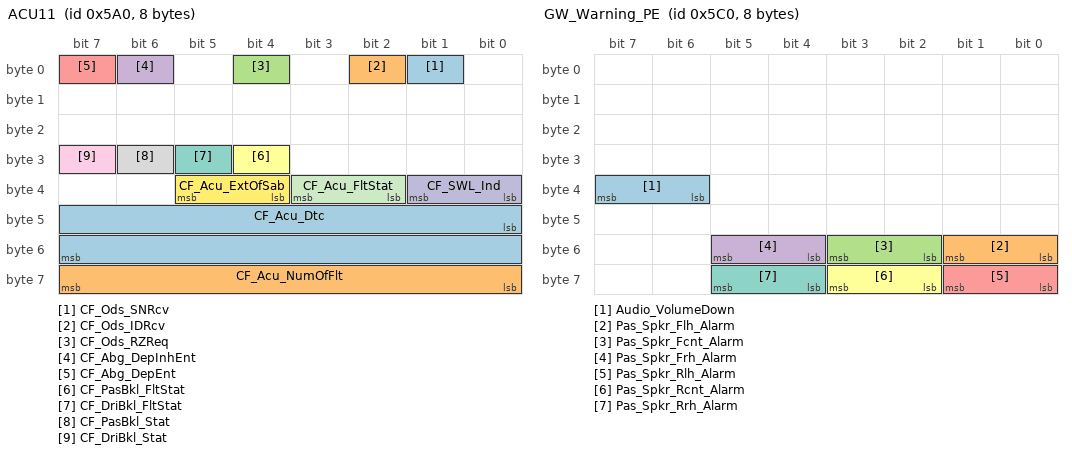
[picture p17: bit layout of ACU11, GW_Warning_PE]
BO_ 1440 ACU11: 8 ACU
    SG_ CF_Ods_SNRcv : 1|1@1+ (1.0,0.0) [0.0|1.0] ""  ODS
    SG_ CF_Ods_IDRcv : 2|1@1+ (1.0,0.0) [0.0|1.0] ""  ODS
    SG_ CF_Ods_RZReq : 4|1@1+ (1.0,0.0) [0.0|1.0] ""  ODS
    SG_ CF_Abg_DepInhEnt : 6|1@1+ (1.0,0.0) [0.0|1.0] ""  ODS
    SG_ CF_Abg_DepEnt : 7|1@1+ (1.0,0.0) [0.0|1.0] ""  ODS
    SG_ CF_PasBkl_FltStat : 28|1@1+ (1.0,0.0) [0.0|1.0] ""  ODS,PSB
    SG_ CF_DriBkl_FltStat : 29|1@1+ (1.0,0.0) [0.0|1.0] ""  ODS,PSB
    SG_ CF_PasBkl_Stat : 30|1@1+ (1.0,0.0) [0.0|1.0] ""  IBOX,ODS,PSB,TMU
    SG_ CF_DriBkl_Stat : 31|1@1+ (1.0,0.0) [0.0|1.0] ""  ODS,PSB
    SG_ CF_SWL_Ind : 32|2@1+ (1.0,0.0) [0.0|3.0] ""  CUBIS,IBOX
    SG_ CF_Acu_FltStat : 34|2@1+ (1.0,0.0) [0.0|3.0] ""  CUBIS,IBOX
    SG_ CF_Acu_ExtOfSab : 36|2@1+ (1.0,0.0) [0.0|3.0] ""  BCM,CLU,CUBIS,IBOX
    SG_ CF_Acu_Dtc : 40|16@1+ (1.0,0.0) [0.0|65535.0] ""  CUBIS,IBOX
    SG_ CF_Acu_NumOfFlt : 56|8@1+ (1.0,0.0) [0.0|255.0] ""  CUBIS,IBOX

BO_ 1472 GW_Warning_PE: 8 BCM
    SG_ Audio_VolumeDown : 38|2@1+ (1.0,0.0) [0.0|3.0] ""  CLU
    SG_ Pas_Spkr_Flh_Alarm : 48|2@1+ (1.0,0.0) [0.0|3.0] ""  CLU
    SG_ Pas_Spkr_Fcnt_Alarm : 50|2@1+ (1.0,0.0) [0.0|3.0] ""  CLU
    SG_ Pas_Spkr_Frh_Alarm : 52|2@1+ (1.0,0.0) [0.0|3.0] ""  CLU
    SG_ Pas_Spkr_Rlh_Alarm : 56|2@1+ (1.0,0.0) [0.0|3.0] ""  CLU,PGS
    SG_ Pas_Spkr_Rcnt_Alarm : 58|2@1+ (1.0,0.0) [0.0|3.0] ""  CLU
    SG_ Pas_Spkr_Rrh_Alarm : 60|2@1+ (1.0,0.0) [0.0|3.0] ""  CLU,PGS

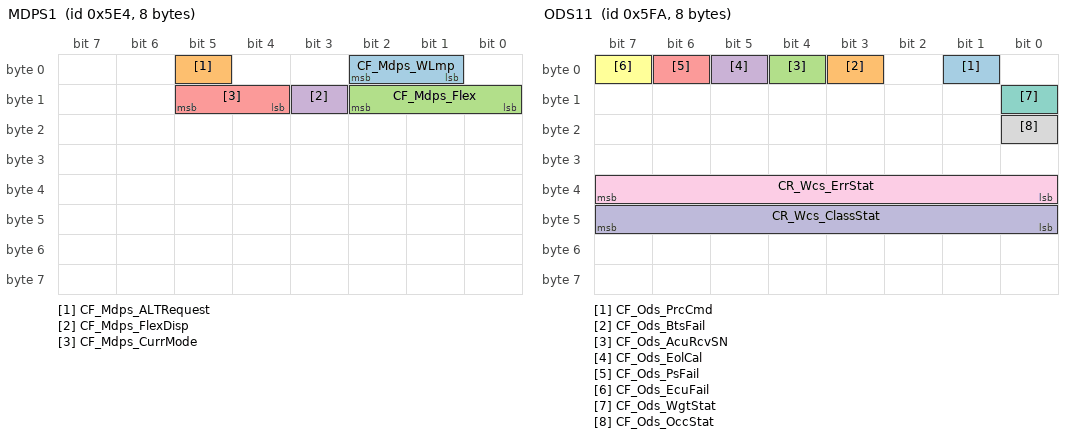
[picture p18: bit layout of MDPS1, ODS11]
BO_ 1508 MDPS1: 8 XXX
    SG_ CF_Mdps_WLmp : 1|2@1+ (1,0) [0|3] "" XXX
    SG_ CF_Mdps_ALTRequest : 5|1@1+ (1,0) [0|1] "" XXX
    SG_ CF_Mdps_Flex : 8|3@1+ (1,0) [0|7] "" XXX
    SG_ CF_Mdps_FlexDisp : 11|1@1+ (1,0) [0|1] "" XXX
    SG_ CF_Mdps_CurrMode : 12|2@1+ (1,0) [0|3] "" XXX

BO_ 1530 ODS11: 8 ODS
    SG_ CF_Ods_PrcCmd : 1|1@1+ (1.0,0.0) [0.0|1.0] ""  Dummy
    SG_ CF_Ods_BtsFail : 3|1@1+ (1.0,0.0) [0.0|1.0] ""  Dummy
    SG_ CF_Ods_AcuRcvSN : 4|1@1+ (1.0,0.0) [0.0|1.0] ""  ACU
    SG_ CF_Ods_EolCal : 5|1@1+ (1.0,0.0) [0.0|1.0] ""  ACU
    SG_ CF_Ods_PsFail : 6|1@1+ (1.0,0.0) [0.0|1.0] ""  ACU
    SG_ CF_Ods_EcuFail : 7|1@1+ (1.0,0.0) [0.0|1.0] ""  ACU
    SG_ CF_Ods_WgtStat : 8|1@1+ (1.0,0.0) [0.0|1.0] ""  ACU
    SG_ CF_Ods_OccStat : 16|1@1+ (1.0,0.0) [0.0|1.0] ""  ACU
    SG_ CR_Wcs_ErrStat : 32|8@1+ (1.0,0.0) [0.0|63.0] ""  ACU
    SG_ CR_Wcs_ClassStat : 40|8@1+ (1.0,0.0) [0.0|4.0] ""  ACU,BCM

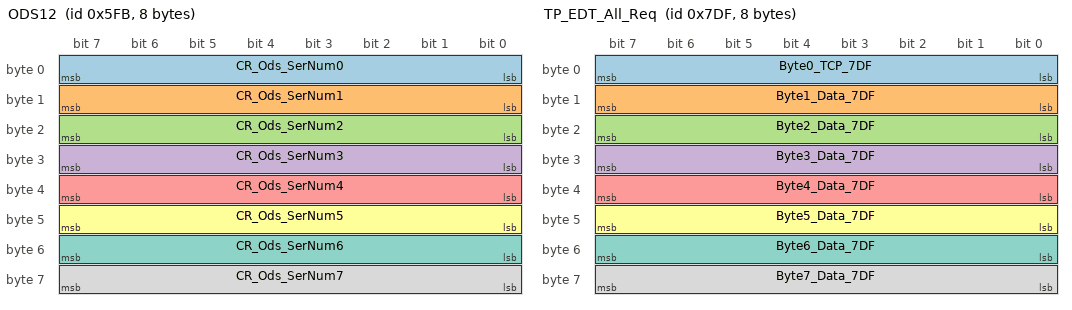
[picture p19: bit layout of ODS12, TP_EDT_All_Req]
BO_ 1531 ODS12: 8 ODS
    SG_ CR_Ods_SerNum0 : 0|8@1+ (1.0,0.0) [0.0|255.0] ""  ACU
    SG_ CR_Ods_SerNum1 : 8|8@1+ (1.0,0.0) [0.0|255.0] ""  ACU
    SG_ CR_Ods_SerNum2 : 16|8@1+ (1.0,0.0) [0.0|255.0] ""  ACU
    SG_ CR_Ods_SerNum3 : 24|8@1+ (1.0,0.0) [0.0|255.0] ""  ACU
    SG_ CR_Ods_SerNum4 : 32|8@1+ (1.0,0.0) [0.0|255.0] ""  ACU
    SG_ CR_Ods_SerNum5 : 40|8@1+ (1.0,0.0) [0.0|255.0] ""  ACU
    SG_ CR_Ods_SerNum6 : 48|8@1+ (1.0,0.0) [0.0|255.0] ""  ACU
    SG_ CR_Ods_SerNum7 : 56|8@1+ (1.0,0.0) [0.0|255.0] ""  ACU

BO_ 1532 ODS13: 5 ODS
    SG_ CR_Ods_ID : 0|8@1+ (1.0,0.0) [0.0|255.0] ""  ACU
    SG_ CR_Ods_Chksum_H : 8|8@1+ (1.0,0.0) [0.0|255.0] ""  Dummy
    SG_ CR_Ods_Chksum_L : 16|8@1+ (1.0,0.0) [0.0|255.0] ""  Dummy
    SG_ CR_Ods_RomID_H : 24|8@1+ (1.0,0.0) [0.0|255.0] ""  Dummy
    SG_ CR_Ods_RomID_L : 32|8@1+ (1.0,0.0) [0.0|255.0] ""  Dummy

BO_ 1680 CLU2: 8 XXX
    SG_ CF_Clu_IGNSw : 0|3@1+ (1,0) [0|7] "" XXX
    SG_ RKE_CMD : 3|3@1+ (1,0) [0|7] "" XXX
    SG_ CF_Clu_DrvDrSw : 6|2@1+ (1,0) [0|3] "" XXX
    SG_ CF_Clu_DrvKeyLockSw : 8|1@1+ (1,0) [0|1] "" XXX
    SG_ CF_Clu_DrvKeyUnlockSw : 9|1@1+ (1,0) [0|1] "" XXX
    SG_ PIC_Lock : 10|3@1+ (1,0) [0|7] "" XXX
    SG_ PIC_Unlock : 13|3@1+ (1,0) [0|7] "" XXX
    SG_ CF_Clu_DrvSeatBeltSw : 16|2@1+ (1,0) [0|3] "" XXX
    SG_ CF_Clu_TrunkTgSw : 18|2@1+ (1,0) [0|3] "" XXX
    SG_ CF_Clu_AstSeatBeltSw : 20|2@1+ (1,0) [0|3] "" XXX
    SG_ CF_Clu_HoodSw : 22|2@1+ (1,0) [0|3] "" XXX
    SG_ CF_Clu_TurnSigLh : 24|1@1+ (1,0) [0|1] "" XXX
    SG_ CF_Clu_TurnSigRh : 25|1@1+ (1,0) [0|1] "" XXX
    SG_ CF_Clu_LdwsLkasSW : 26|1@1+ (1,0) [0|1] "" XXX
    SG_ CF_Clu_WiperIntT : 27|3@1+ (1,0) [0|7] "" XXX
    SG_ CF_Clu_WiperIntSW : 30|1@1+ (1,0) [0|1] "" XXX
    SG_ CF_Clu_WiperLow : 31|1@1+ (1,0) [0|1] "" XXX
    SG_ CF_Clu_WiperHigh : 32|1@1+ (1,0) [0|1] "" XXX
    SG_ CF_Clu_WiperAuto : 33|1@1+ (1,0) [0|1] "" XXX
    SG_ CF_Clu_RainSnsStat : 34|3@1+ (1,0) [0|7] "" XXX
    SG_ CF_Clu_HeadLampLow : 37|1@1+ (1,0) [0|1] "" XXX
    SG_ CF_Clu_HeadLampHigh : 38|1@1+ (1,0) [0|1] "" XXX
    SG_ CF_Clu_AltLStatus : 39|1@1+ (1,0) [0|1] "" XXX
    SG_ CF_Clu_EcoDriveInf : 40|3@1+ (1,0) [0|7] "" XXX
    SG_ CF_Clu_SwiGearR : 43|2@1+ (1,0) [0|3] "" XXX
    SG_ CF_Clu_SWL_Stat : 45|3@1+ (1,0) [0|7] "" XXX
    SG_ CF_Clu_ActiveEcoSW : 48|1@1+ (1,0) [0|1] "" XXX
    SG_ CF_Clu_HazardSW : 49|1@1+ (1,0) [0|1] "" XXX
    SG_ CF_Clu_AliveCnt2 : 50|4@1+ (1,0) [0|15] "" XXX
    SG_ CF_Clu_AstDrSw : 54|2@1+ (1,0) [0|3] "" XXX
    SG_ CF_Clu_LkasDispMode : 56|2@1+ (1,0) [0|3] "" XXX
    SG_ CF_Clu_AutoLightLevel : 58|2@1+ (1,0) [0|3] "" XXX
    SG_ CF_Clu_SunRoofOpenState : 60|1@1+ (1,0) [0|1] "" XXX

BO_ 2015 TP_EDT_All_Req: 8 EDT
    SG_ Byte0_TCP_7DF : 7|8@0+ (1,0) [0|0] ""  AMP,ASD,AVM,CCP,CGW,CLOCK,CLU,CUBIS,DATC,FHCU,HUD,H_U,IBOX,IPM,KBD,KMA_TMU,MON,RRC,RSE_L,RSE_R,TMU
    SG_ Byte1_Data_7DF : 15|8@0+ (1,0) [0|0] ""  AMP,ASD,AVM,CCP,CGW,CLOCK,CLU,CUBIS,DATC,FHCU,HUD,H_U,IBOX,IPM,KBD,KMA_TMU,MON,RRC,RSE_L,RSE_R,TMU
    SG_ Byte2_Data_7DF : 23|8@0+ (1,0) [0|0] ""  AMP,ASD,AVM,CCP,CGW,CLOCK,CLU,CUBIS,DATC,FHCU,HUD,H_U,IBOX,IPM,KBD,KMA_TMU,MON,RRC,RSE_L,RSE_R,TMU
    SG_ Byte3_Data_7DF : 31|8@0+ (1,0) [0|0] ""  AMP,ASD,AVM,CCP,CGW,CLOCK,CLU,CUBIS,DATC,FHCU,HUD,H_U,IBOX,IPM,KBD,KMA_TMU,MON,RRC,RSE_L,RSE_R,TMU
    SG_ Byte4_Data_7DF : 39|8@0+ (1,0) [0|0] ""  AMP,ASD,AVM,CCP,CGW,CLOCK,CLU,CUBIS,DATC,FHCU,HUD,H_U,IBOX,IPM,KBD,KMA_TMU,MON,RRC,RSE_L,RSE_R,TMU
    SG_ Byte5_Data_7DF : 47|8@0+ (1,0) [0|0] ""  AMP,ASD,AVM,CCP,CGW,CLOCK,CLU,CUBIS,DATC,FHCU,HUD,H_U,IBOX,IPM,KBD,KMA_TMU,MON,RRC,RSE_L,RSE_R,TMU
    SG_ Byte6_Data_7DF : 55|8@0+ (1,0) [0|0] ""  AMP,ASD,AVM,CCP,CGW,CLOCK,CLU,CUBIS,DATC,FHCU,HUD,H_U,IBOX,IPM,KBD,KMA_TMU,MON,RRC,RSE_L,RSE_R,TMU
    SG_ Byte7_Data_7DF : 63|8@0+ (1,0) [0|0] ""  AMP,ASD,AVM,CCP,CGW,CLOCK,CLU,CUBIS,DATC,FHCU,HUD,H_U,IBOX,IPM,KBD,KMA_TMU,MON,RRC,RSE_L,RSE_R,TMU
